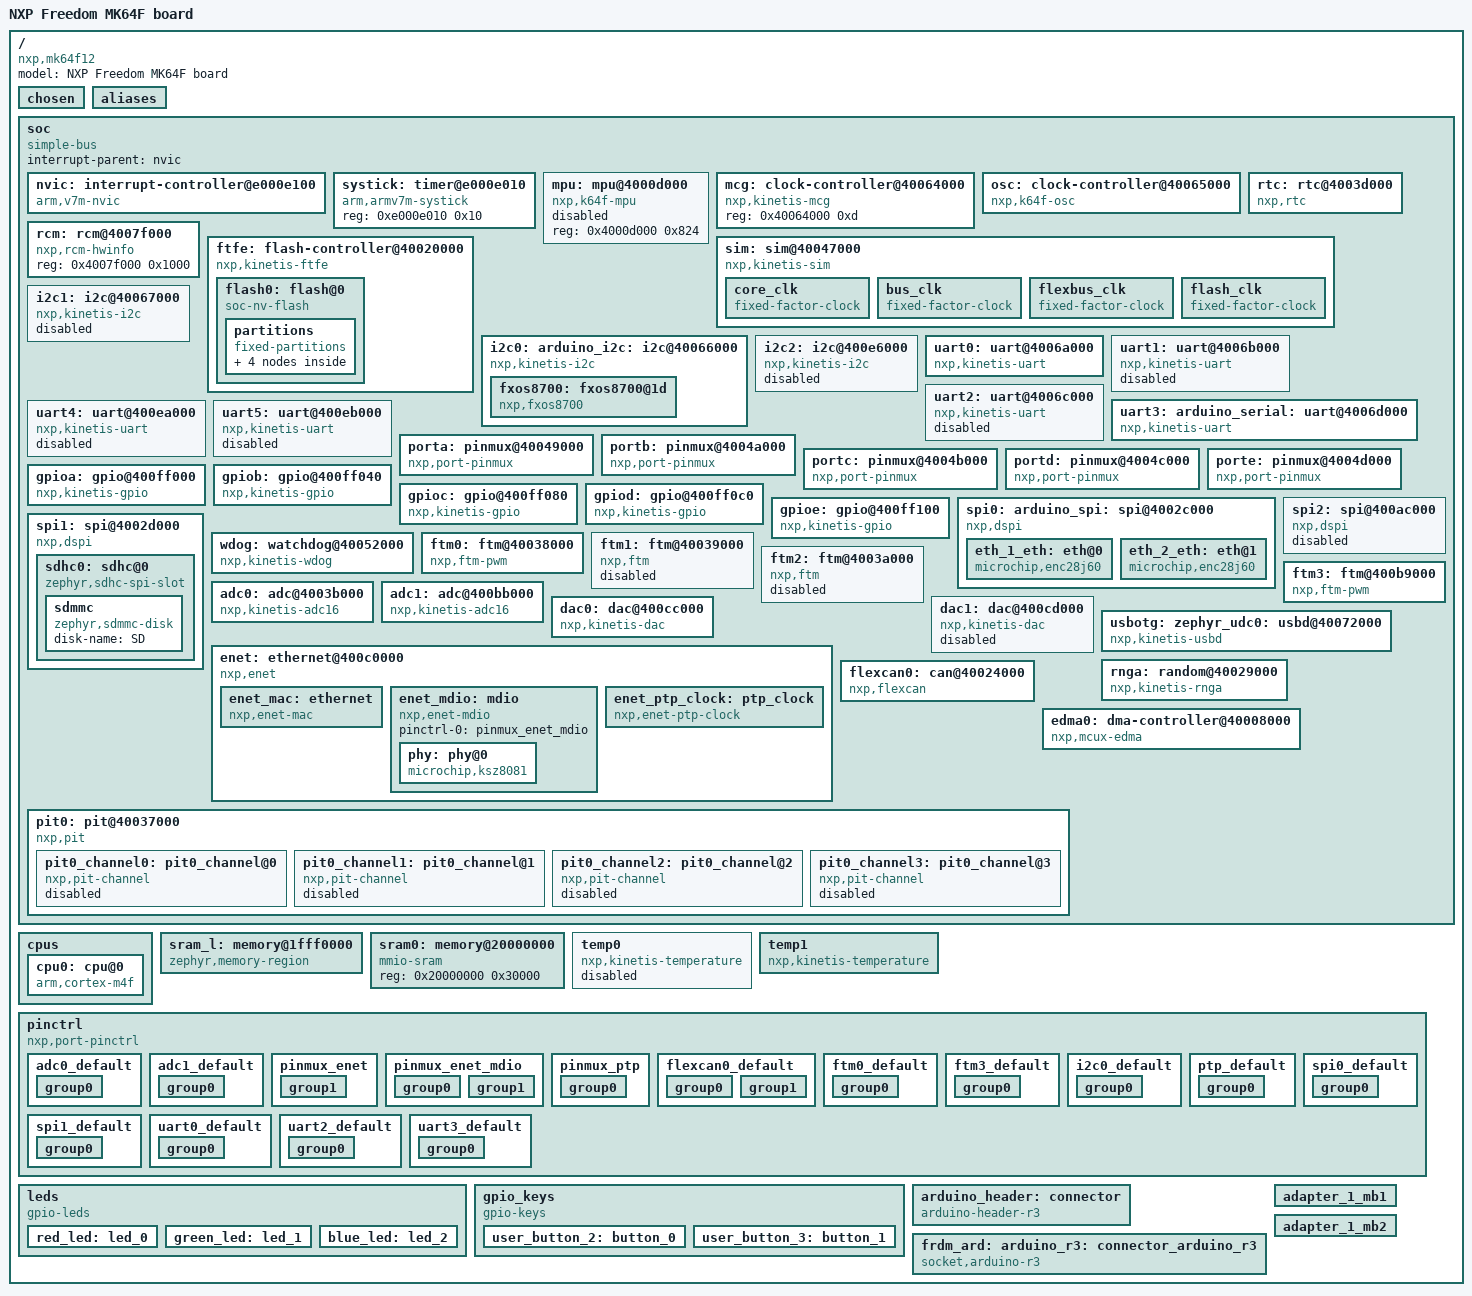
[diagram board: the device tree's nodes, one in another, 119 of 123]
/dts-v1/;

/* node '/' defined in zephyr/dts/common/skeleton.dtsi:9 */
/ {
	#address-cells = < 0x1 >;          /* in zephyr/dts/common/skeleton.dtsi:10 */
	#size-cells = < 0x1 >;             /* in zephyr/dts/common/skeleton.dtsi:11 */
	model = "NXP Freedom MK64F board"; /* in zephyr/boards/nxp/frdm_k64f/frdm_k64f.dts:15 */
	compatible = "nxp,mk64f12",
	             "nxp,k64f",
	             "nxp,k6x";            /* in zephyr/boards/nxp/frdm_k64f/frdm_k64f.dts:16 */

	/* node '/chosen' defined in zephyr/dts/common/skeleton.dtsi:13 */
	chosen {
		zephyr,entropy = &rnga;                   /* in zephyr/dts/arm/nxp/kinetis/nxp_k6x.dtsi:22 */
		zephyr,flash-controller = &ftfe;          /* in zephyr/dts/arm/nxp/kinetis/nxp_k6x.dtsi:23 */
		zephyr,sram = &sram0;                     /* in zephyr/boards/nxp/frdm_k64f/frdm_k64f.dts:30 */
		zephyr,flash = &flash0;                   /* in zephyr/boards/nxp/frdm_k64f/frdm_k64f.dts:31 */
		zephyr,code-partition = &slot0_partition; /* in zephyr/boards/nxp/frdm_k64f/frdm_k64f.dts:32 */
		zephyr,console = &uart0;                  /* in zephyr/boards/nxp/frdm_k64f/frdm_k64f.dts:33 */
		zephyr,shell-uart = &uart0;               /* in zephyr/boards/nxp/frdm_k64f/frdm_k64f.dts:34 */
		zephyr,uart-pipe = &uart0;                /* in zephyr/boards/nxp/frdm_k64f/frdm_k64f.dts:35 */
		zephyr,canbus = &flexcan0;                /* in zephyr/boards/nxp/frdm_k64f/frdm_k64f.dts:36 */
		zephyr,uart-mcumgr = &uart0;              /* in zephyr/boards/nxp/frdm_k64f/frdm_k64f.dts:37 */
	};

	/* node '/aliases' defined in zephyr/dts/common/skeleton.dtsi:15 */
	aliases {
		watchdog0 = &wdog;                /* in zephyr/dts/arm/nxp/kinetis/nxp_k6x.dtsi:18 */
		led0 = &green_led;                /* in zephyr/boards/nxp/frdm_k64f/frdm_k64f.dts:19 */
		led1 = &blue_led;                 /* in zephyr/boards/nxp/frdm_k64f/frdm_k64f.dts:20 */
		led2 = &red_led;                  /* in zephyr/boards/nxp/frdm_k64f/frdm_k64f.dts:21 */
		sw0 = &user_button_3;             /* in zephyr/boards/nxp/frdm_k64f/frdm_k64f.dts:22 */
		sw1 = &user_button_2;             /* in zephyr/boards/nxp/frdm_k64f/frdm_k64f.dts:23 */
		magn0 = &fxos8700;                /* in zephyr/boards/nxp/frdm_k64f/frdm_k64f.dts:24 */
		accel0 = &fxos8700;               /* in zephyr/boards/nxp/frdm_k64f/frdm_k64f.dts:25 */
		mcuboot-button0 = &user_button_2; /* in zephyr/boards/nxp/frdm_k64f/frdm_k64f.dts:26 */
	};

	/* node '/soc' defined in zephyr/dts/arm/armv7-m.dtsi:6 */
	soc {
		#address-cells = < 0x1 >;     /* in zephyr/dts/arm/armv7-m.dtsi:7 */
		#size-cells = < 0x1 >;        /* in zephyr/dts/arm/armv7-m.dtsi:8 */
		compatible = "simple-bus";    /* in zephyr/dts/arm/armv7-m.dtsi:9 */
		interrupt-parent = < &nvic >; /* in zephyr/dts/arm/armv7-m.dtsi:10 */
		ranges;                       /* in zephyr/dts/arm/armv7-m.dtsi:11 */

		/* node '/soc/interrupt-controller@e000e100' defined in zephyr/dts/arm/armv7-m.dtsi:13 */
		nvic: interrupt-controller@e000e100 {
			#address-cells = < 0x1 >;            /* in zephyr/dts/arm/armv7-m.dtsi:14 */
			compatible = "arm,v7m-nvic";         /* in zephyr/dts/arm/armv7-m.dtsi:15 */
			reg = < 0xe000e100 0xc00 >;          /* in zephyr/dts/arm/armv7-m.dtsi:16 */
			interrupt-controller;                /* in zephyr/dts/arm/armv7-m.dtsi:17 */
			#interrupt-cells = < 0x2 >;          /* in zephyr/dts/arm/armv7-m.dtsi:18 */
			arm,num-irq-priority-bits = < 0x4 >; /* in zephyr/dts/arm/nxp/kinetis/nxp_k6x.dtsi:599 */
			phandle = < 0x1 >;                   /* in zephyr/dts/arm/armv7-m.dtsi:10 */
		};

		/* node '/soc/timer@e000e010' defined in zephyr/dts/arm/armv7-m.dtsi:21 */
		systick: timer@e000e010 {
			compatible = "arm,armv7m-systick"; /* in zephyr/dts/arm/armv7-m.dtsi:22 */
			reg = < 0xe000e010 0x10 >;         /* in zephyr/dts/arm/armv7-m.dtsi:23 */
		};

		/* node '/soc/mpu@4000d000' defined in zephyr/dts/arm/nxp/kinetis/nxp_k6x.dtsi:86 */
		mpu: mpu@4000d000 {
			compatible = "nxp,k64f-mpu"; /* in zephyr/dts/arm/nxp/kinetis/nxp_k6x.dtsi:87 */
			reg = < 0x4000d000 0x824 >;  /* in zephyr/dts/arm/nxp/kinetis/nxp_k6x.dtsi:88 */
			status = "disabled";         /* in zephyr/dts/arm/nxp/kinetis/nxp_k6x.dtsi:90 */
		};

		/* node '/soc/clock-controller@40064000' defined in zephyr/dts/arm/nxp/kinetis/nxp_k6x.dtsi:93 */
		mcg: clock-controller@40064000 {
			compatible = "nxp,kinetis-mcg"; /* in zephyr/dts/arm/nxp/kinetis/nxp_k6x.dtsi:94 */
			reg = < 0x40064000 0xd >;       /* in zephyr/dts/arm/nxp/kinetis/nxp_k6x.dtsi:95 */
			#clock-cells = < 0x1 >;         /* in zephyr/dts/arm/nxp/kinetis/nxp_k6x.dtsi:96 */
			phandle = < 0x2 >;              /* in zephyr/dts/arm/nxp/kinetis/nxp_k6x.dtsi:127 */
		};

		/* node '/soc/clock-controller@40065000' defined in zephyr/dts/arm/nxp/kinetis/nxp_k6x.dtsi:99 */
		osc: clock-controller@40065000 {
			compatible = "nxp,k64f-osc"; /* in zephyr/dts/arm/nxp/kinetis/nxp_k6x.dtsi:100 */
			reg = < 0x40065000 0x4 >;    /* in zephyr/dts/arm/nxp/kinetis/nxp_k6x.dtsi:101 */
			enable-external-reference;   /* in zephyr/dts/arm/nxp/kinetis/nxp_k6x.dtsi:103 */
		};

		/* node '/soc/rtc@4003d000' defined in zephyr/dts/arm/nxp/kinetis/nxp_k6x.dtsi:106 */
		rtc: rtc@4003d000 {
			compatible = "nxp,rtc";       /* in zephyr/dts/arm/nxp/kinetis/nxp_k6x.dtsi:107 */
			reg = < 0x4003d000 0x1000 >;  /* in zephyr/dts/arm/nxp/kinetis/nxp_k6x.dtsi:108 */
			interrupts = < 0x2e 0x0 >,
			             < 0x2f 0x0 >;    /* in zephyr/dts/arm/nxp/kinetis/nxp_k6x.dtsi:109 */
			interrupt-names = "alarm",
			                  "seconds";  /* in zephyr/dts/arm/nxp/kinetis/nxp_k6x.dtsi:110 */
			clock-frequency = < 0x8000 >; /* in zephyr/dts/arm/nxp/kinetis/nxp_k6x.dtsi:111 */
			prescaler = < 0x8000 >;       /* in zephyr/dts/arm/nxp/kinetis/nxp_k6x.dtsi:112 */
		};

		/* node '/soc/rcm@4007f000' defined in zephyr/dts/arm/nxp/kinetis/nxp_k6x.dtsi:115 */
		rcm: rcm@4007f000 {
			compatible = "nxp,rcm-hwinfo"; /* in zephyr/dts/arm/nxp/kinetis/nxp_k6x.dtsi:116 */
			reg = < 0x4007f000 0x1000 >;   /* in zephyr/dts/arm/nxp/kinetis/nxp_k6x.dtsi:117 */
		};

		/* node '/soc/sim@40047000' defined in zephyr/dts/arm/nxp/kinetis/nxp_k6x.dtsi:120 */
		sim: sim@40047000 {
			compatible = "nxp,kinetis-sim",
			             "nxp,sim-uuid";    /* in zephyr/dts/arm/nxp/kinetis/nxp_k6x.dtsi:121 */
			reg = < 0x40047000 0x1060 >;    /* in zephyr/dts/arm/nxp/kinetis/nxp_k6x.dtsi:122 */
			#clock-cells = < 0x3 >;         /* in zephyr/dts/arm/nxp/kinetis/nxp_k6x.dtsi:123 */
			pllfll-select = < 0x1 >;        /* in zephyr/boards/nxp/frdm_k64f/frdm_k64f.dts:109 */
			er32k-select = < 0x2 >;         /* in zephyr/boards/nxp/frdm_k64f/frdm_k64f.dts:110 */
			phandle = < 0x3 >;              /* in zephyr/dts/arm/nxp/kinetis/nxp_k6x.dtsi:179 */

			/* node '/soc/sim@40047000/core_clk' defined in zephyr/dts/arm/nxp/kinetis/nxp_k6x.dtsi:125 */
			core_clk {
				compatible = "fixed-factor-clock"; /* in zephyr/dts/arm/nxp/kinetis/nxp_k6x.dtsi:126 */
				clocks = < &mcg 0x1 >;             /* in zephyr/dts/arm/nxp/kinetis/nxp_k6x.dtsi:127 */
				clock-div = < 0x1 >;               /* in zephyr/dts/arm/nxp/kinetis/nxp_k6x.dtsi:128 */
				#clock-cells = < 0x0 >;            /* in zephyr/dts/arm/nxp/kinetis/nxp_k6x.dtsi:129 */
			};

			/* node '/soc/sim@40047000/bus_clk' defined in zephyr/dts/arm/nxp/kinetis/nxp_k6x.dtsi:132 */
			bus_clk {
				compatible = "fixed-factor-clock"; /* in zephyr/dts/arm/nxp/kinetis/nxp_k6x.dtsi:133 */
				clocks = < &mcg 0x1 >;             /* in zephyr/dts/arm/nxp/kinetis/nxp_k6x.dtsi:134 */
				clock-div = < 0x2 >;               /* in zephyr/dts/arm/nxp/kinetis/nxp_k6x.dtsi:135 */
				#clock-cells = < 0x0 >;            /* in zephyr/dts/arm/nxp/kinetis/nxp_k6x.dtsi:136 */
			};

			/* node '/soc/sim@40047000/flexbus_clk' defined in zephyr/dts/arm/nxp/kinetis/nxp_k6x.dtsi:139 */
			flexbus_clk {
				compatible = "fixed-factor-clock"; /* in zephyr/dts/arm/nxp/kinetis/nxp_k6x.dtsi:140 */
				clocks = < &mcg 0x1 >;             /* in zephyr/dts/arm/nxp/kinetis/nxp_k6x.dtsi:141 */
				clock-div = < 0x3 >;               /* in zephyr/dts/arm/nxp/kinetis/nxp_k6x.dtsi:142 */
				#clock-cells = < 0x0 >;            /* in zephyr/dts/arm/nxp/kinetis/nxp_k6x.dtsi:143 */
			};

			/* node '/soc/sim@40047000/flash_clk' defined in zephyr/dts/arm/nxp/kinetis/nxp_k6x.dtsi:146 */
			flash_clk {
				compatible = "fixed-factor-clock"; /* in zephyr/dts/arm/nxp/kinetis/nxp_k6x.dtsi:147 */
				clocks = < &mcg 0x1 >;             /* in zephyr/dts/arm/nxp/kinetis/nxp_k6x.dtsi:148 */
				clock-div = < 0x5 >;               /* in zephyr/dts/arm/nxp/kinetis/nxp_k6x.dtsi:149 */
				#clock-cells = < 0x0 >;            /* in zephyr/dts/arm/nxp/kinetis/nxp_k6x.dtsi:150 */
			};
		};

		/* node '/soc/flash-controller@40020000' defined in zephyr/dts/arm/nxp/kinetis/nxp_k6x.dtsi:154 */
		ftfe: flash-controller@40020000 {
			compatible = "nxp,kinetis-ftfe";      /* in zephyr/dts/arm/nxp/kinetis/nxp_k6x.dtsi:155 */
			reg = < 0x40020000 0x18 >;            /* in zephyr/dts/arm/nxp/kinetis/nxp_k6x.dtsi:156 */
			interrupts = < 0x12 0x0 >,
			             < 0x13 0x0 >;            /* in zephyr/dts/arm/nxp/kinetis/nxp_k6x.dtsi:157 */
			interrupt-names = "command-complete",
			                  "read-collision";   /* in zephyr/dts/arm/nxp/kinetis/nxp_k6x.dtsi:158 */
			status = "okay";                      /* in zephyr/dts/arm/nxp/kinetis/nxp_k6x.dtsi:159 */
			#address-cells = < 0x1 >;             /* in zephyr/dts/arm/nxp/kinetis/nxp_k6x.dtsi:161 */
			#size-cells = < 0x1 >;                /* in zephyr/dts/arm/nxp/kinetis/nxp_k6x.dtsi:162 */

			/* node '/soc/flash-controller@40020000/flash@0' defined in zephyr/dts/arm/nxp/kinetis/nxp_k6x.dtsi:164 */
			flash0: flash@0 {
				compatible = "soc-nv-flash";   /* in zephyr/dts/arm/nxp/kinetis/nxp_k6x.dtsi:165 */
				reg = < 0x0 0x100000 >;        /* in zephyr/dts/arm/nxp/kinetis/nxp_k6x.dtsi:166 */
				erase-block-size = < 0x1000 >; /* in zephyr/dts/arm/nxp/kinetis/nxp_k6x.dtsi:167 */
				write-block-size = < 0x8 >;    /* in zephyr/dts/arm/nxp/kinetis/nxp_k6x.dtsi:168 */

				/* node '/soc/flash-controller@40020000/flash@0/partitions' defined in zephyr/boards/nxp/frdm_k64f/frdm_k64f.dts:242 */
				partitions {
					compatible = "fixed-partitions"; /* in zephyr/boards/nxp/frdm_k64f/frdm_k64f.dts:243 */
					#address-cells = < 0x1 >;        /* in zephyr/boards/nxp/frdm_k64f/frdm_k64f.dts:244 */
					#size-cells = < 0x1 >;           /* in zephyr/boards/nxp/frdm_k64f/frdm_k64f.dts:245 */

					/* node '/soc/flash-controller@40020000/flash@0/partitions/partition@0' defined in zephyr/boards/nxp/frdm_k64f/frdm_k64f.dts:251 */
					boot_partition: partition@0 {
						label = "mcuboot";     /* in zephyr/boards/nxp/frdm_k64f/frdm_k64f.dts:252 */
						reg = < 0x0 0x10000 >; /* in zephyr/boards/nxp/frdm_k64f/frdm_k64f.dts:253 */
						read-only;             /* in zephyr/boards/nxp/frdm_k64f/frdm_k64f.dts:254 */
					};

					/* node '/soc/flash-controller@40020000/flash@0/partitions/partition@10000' defined in zephyr/boards/nxp/frdm_k64f/frdm_k64f.dts:257 */
					slot0_partition: partition@10000 {
						label = "image-0";         /* in zephyr/boards/nxp/frdm_k64f/frdm_k64f.dts:258 */
						reg = < 0x10000 0x69000 >; /* in zephyr/boards/nxp/frdm_k64f/frdm_k64f.dts:259 */
					};

					/* node '/soc/flash-controller@40020000/flash@0/partitions/partition@79000' defined in zephyr/boards/nxp/frdm_k64f/frdm_k64f.dts:262 */
					slot1_partition: partition@79000 {
						label = "image-1";         /* in zephyr/boards/nxp/frdm_k64f/frdm_k64f.dts:263 */
						reg = < 0x79000 0x69000 >; /* in zephyr/boards/nxp/frdm_k64f/frdm_k64f.dts:264 */
					};

					/* node '/soc/flash-controller@40020000/flash@0/partitions/partition@e2000' defined in zephyr/boards/nxp/frdm_k64f/frdm_k64f.dts:267 */
					storage_partition: partition@e2000 {
						label = "storage";         /* in zephyr/boards/nxp/frdm_k64f/frdm_k64f.dts:268 */
						reg = < 0xe2000 0x1e000 >; /* in zephyr/boards/nxp/frdm_k64f/frdm_k64f.dts:269 */
					};
				};
			};
		};

		/* node '/soc/i2c@40066000' defined in zephyr/dts/arm/nxp/kinetis/nxp_k6x.dtsi:172 */
		i2c0: arduino_i2c: i2c@40066000 {
			compatible = "nxp,kinetis-i2c";          /* in zephyr/dts/arm/nxp/kinetis/nxp_k6x.dtsi:173 */
			clock-frequency = < 0x186a0 >;           /* in zephyr/dts/arm/nxp/kinetis/nxp_k6x.dtsi:174 */
			#address-cells = < 0x1 >;                /* in zephyr/dts/arm/nxp/kinetis/nxp_k6x.dtsi:175 */
			#size-cells = < 0x0 >;                   /* in zephyr/dts/arm/nxp/kinetis/nxp_k6x.dtsi:176 */
			reg = < 0x40066000 0x1000 >;             /* in zephyr/dts/arm/nxp/kinetis/nxp_k6x.dtsi:177 */
			interrupts = < 0x18 0x0 >;               /* in zephyr/dts/arm/nxp/kinetis/nxp_k6x.dtsi:178 */
			clocks = < &sim 0x81a18400 0x1034 0x6 >; /* in zephyr/dts/arm/nxp/kinetis/nxp_k6x.dtsi:179 */
			status = "okay";                         /* in zephyr/boards/nxp/frdm_k64f/frdm_k64f.dts:146 */
			pinctrl-0 = < &i2c0_default >;           /* in zephyr/boards/nxp/frdm_k64f/frdm_k64f.dts:147 */
			pinctrl-names = "default";               /* in zephyr/boards/nxp/frdm_k64f/frdm_k64f.dts:148 */
			phandle = < 0x24 >;                      /* in btr-shields/boards/extend/nxp/frdm_k64f/arduino_r3_socket.dtsi:59 */

			/* node '/soc/i2c@40066000/fxos8700@1d' defined in zephyr/boards/nxp/frdm_k64f/frdm_k64f.dts:150 */
			fxos8700: fxos8700@1d {
				compatible = "nxp,fxos8700";     /* in zephyr/boards/nxp/frdm_k64f/frdm_k64f.dts:151 */
				reg = < 0x1d >;                  /* in zephyr/boards/nxp/frdm_k64f/frdm_k64f.dts:152 */
				int1-gpios = < &gpioc 0x6 0x1 >; /* in zephyr/boards/nxp/frdm_k64f/frdm_k64f.dts:153 */
				int2-gpios = < &gpioc 0xd 0x1 >; /* in zephyr/boards/nxp/frdm_k64f/frdm_k64f.dts:154 */
			};
		};

		/* node '/soc/i2c@40067000' defined in zephyr/dts/arm/nxp/kinetis/nxp_k6x.dtsi:183 */
		i2c1: i2c@40067000 {
			compatible = "nxp,kinetis-i2c";          /* in zephyr/dts/arm/nxp/kinetis/nxp_k6x.dtsi:184 */
			clock-frequency = < 0x186a0 >;           /* in zephyr/dts/arm/nxp/kinetis/nxp_k6x.dtsi:185 */
			#address-cells = < 0x1 >;                /* in zephyr/dts/arm/nxp/kinetis/nxp_k6x.dtsi:186 */
			#size-cells = < 0x0 >;                   /* in zephyr/dts/arm/nxp/kinetis/nxp_k6x.dtsi:187 */
			reg = < 0x40067000 0x1000 >;             /* in zephyr/dts/arm/nxp/kinetis/nxp_k6x.dtsi:188 */
			interrupts = < 0x19 0x0 >;               /* in zephyr/dts/arm/nxp/kinetis/nxp_k6x.dtsi:189 */
			clocks = < &sim 0x81a1c400 0x1034 0x7 >; /* in zephyr/dts/arm/nxp/kinetis/nxp_k6x.dtsi:190 */
			status = "disabled";                     /* in zephyr/dts/arm/nxp/kinetis/nxp_k6x.dtsi:191 */
		};

		/* node '/soc/i2c@400e6000' defined in zephyr/dts/arm/nxp/kinetis/nxp_k6x.dtsi:194 */
		i2c2: i2c@400e6000 {
			compatible = "nxp,kinetis-i2c";          /* in zephyr/dts/arm/nxp/kinetis/nxp_k6x.dtsi:195 */
			clock-frequency = < 0x186a0 >;           /* in zephyr/dts/arm/nxp/kinetis/nxp_k6x.dtsi:196 */
			#address-cells = < 0x1 >;                /* in zephyr/dts/arm/nxp/kinetis/nxp_k6x.dtsi:197 */
			#size-cells = < 0x0 >;                   /* in zephyr/dts/arm/nxp/kinetis/nxp_k6x.dtsi:198 */
			reg = < 0x400e6000 0x1000 >;             /* in zephyr/dts/arm/nxp/kinetis/nxp_k6x.dtsi:199 */
			interrupts = < 0x4a 0x0 >;               /* in zephyr/dts/arm/nxp/kinetis/nxp_k6x.dtsi:200 */
			clocks = < &sim 0x81418400 0x1028 0x6 >; /* in zephyr/dts/arm/nxp/kinetis/nxp_k6x.dtsi:201 */
			status = "disabled";                     /* in zephyr/dts/arm/nxp/kinetis/nxp_k6x.dtsi:202 */
		};

		/* node '/soc/uart@4006a000' defined in zephyr/dts/arm/nxp/kinetis/nxp_k6x.dtsi:205 */
		uart0: uart@4006a000 {
			compatible = "nxp,kinetis-uart";         /* in zephyr/dts/arm/nxp/kinetis/nxp_k6x.dtsi:206 */
			reg = < 0x4006a000 0x1000 >;             /* in zephyr/dts/arm/nxp/kinetis/nxp_k6x.dtsi:207 */
			interrupts = < 0x1f 0x0 >,
			             < 0x20 0x0 >;               /* in zephyr/dts/arm/nxp/kinetis/nxp_k6x.dtsi:208 */
			interrupt-names = "status",
			                  "error";               /* in zephyr/dts/arm/nxp/kinetis/nxp_k6x.dtsi:209 */
			clocks = < &sim 0x81a28000 0x1034 0xa >; /* in zephyr/dts/arm/nxp/kinetis/nxp_k6x.dtsi:210 */
			status = "okay";                         /* in zephyr/boards/nxp/frdm_k64f/frdm_k64f.dts:204 */
			current-speed = < 0x1c200 >;             /* in zephyr/boards/nxp/frdm_k64f/frdm_k64f.dts:205 */
			pinctrl-0 = < &uart0_default >;          /* in zephyr/boards/nxp/frdm_k64f/frdm_k64f.dts:206 */
			pinctrl-names = "default";               /* in zephyr/boards/nxp/frdm_k64f/frdm_k64f.dts:207 */
		};

		/* node '/soc/uart@4006b000' defined in zephyr/dts/arm/nxp/kinetis/nxp_k6x.dtsi:215 */
		uart1: uart@4006b000 {
			compatible = "nxp,kinetis-uart";         /* in zephyr/dts/arm/nxp/kinetis/nxp_k6x.dtsi:216 */
			reg = < 0x4006b000 0x1000 >;             /* in zephyr/dts/arm/nxp/kinetis/nxp_k6x.dtsi:217 */
			interrupts = < 0x21 0x0 >,
			             < 0x22 0x0 >;               /* in zephyr/dts/arm/nxp/kinetis/nxp_k6x.dtsi:218 */
			interrupt-names = "status",
			                  "error";               /* in zephyr/dts/arm/nxp/kinetis/nxp_k6x.dtsi:219 */
			clocks = < &sim 0x81a2c000 0x1034 0xb >; /* in zephyr/dts/arm/nxp/kinetis/nxp_k6x.dtsi:220 */
			status = "disabled";                     /* in zephyr/dts/arm/nxp/kinetis/nxp_k6x.dtsi:222 */
		};

		/* node '/soc/uart@4006c000' defined in zephyr/dts/arm/nxp/kinetis/nxp_k6x.dtsi:225 */
		uart2: uart@4006c000 {
			compatible = "nxp,kinetis-uart";         /* in zephyr/dts/arm/nxp/kinetis/nxp_k6x.dtsi:226 */
			reg = < 0x4006c000 0x1000 >;             /* in zephyr/dts/arm/nxp/kinetis/nxp_k6x.dtsi:227 */
			interrupts = < 0x23 0x0 >,
			             < 0x24 0x0 >;               /* in zephyr/dts/arm/nxp/kinetis/nxp_k6x.dtsi:228 */
			interrupt-names = "status",
			                  "error";               /* in zephyr/dts/arm/nxp/kinetis/nxp_k6x.dtsi:229 */
			clocks = < &sim 0x81a30400 0x1034 0xc >; /* in zephyr/dts/arm/nxp/kinetis/nxp_k6x.dtsi:230 */
			status = "disabled";                     /* in zephyr/dts/arm/nxp/kinetis/nxp_k6x.dtsi:232 */
			pinctrl-0 = < &uart2_default >;          /* in zephyr/boards/nxp/frdm_k64f/frdm_k64f.dts:211 */
			pinctrl-names = "default";               /* in zephyr/boards/nxp/frdm_k64f/frdm_k64f.dts:212 */
		};

		/* node '/soc/uart@4006d000' defined in zephyr/dts/arm/nxp/kinetis/nxp_k6x.dtsi:235 */
		uart3: arduino_serial: uart@4006d000 {
			compatible = "nxp,kinetis-uart";         /* in zephyr/dts/arm/nxp/kinetis/nxp_k6x.dtsi:236 */
			reg = < 0x4006d000 0x1000 >;             /* in zephyr/dts/arm/nxp/kinetis/nxp_k6x.dtsi:237 */
			interrupts = < 0x25 0x0 >,
			             < 0x26 0x0 >;               /* in zephyr/dts/arm/nxp/kinetis/nxp_k6x.dtsi:238 */
			interrupt-names = "status",
			                  "error";               /* in zephyr/dts/arm/nxp/kinetis/nxp_k6x.dtsi:239 */
			clocks = < &sim 0x81a34400 0x1034 0xd >; /* in zephyr/dts/arm/nxp/kinetis/nxp_k6x.dtsi:240 */
			status = "okay";                         /* in zephyr/boards/nxp/frdm_k64f/frdm_k64f.dts:114 */
			current-speed = < 0x1c200 >;             /* in zephyr/boards/nxp/frdm_k64f/frdm_k64f.dts:115 */
			pinctrl-0 = < &uart3_default >;          /* in zephyr/boards/nxp/frdm_k64f/frdm_k64f.dts:116 */
			pinctrl-names = "default";               /* in zephyr/boards/nxp/frdm_k64f/frdm_k64f.dts:117 */
			phandle = < 0x26 >;                      /* in btr-shields/boards/extend/nxp/frdm_k64f/arduino_r3_socket.dtsi:61 */
		};

		/* node '/soc/uart@400ea000' defined in zephyr/dts/arm/nxp/kinetis/nxp_k6x.dtsi:245 */
		uart4: uart@400ea000 {
			compatible = "nxp,kinetis-uart";         /* in zephyr/dts/arm/nxp/kinetis/nxp_k6x.dtsi:246 */
			reg = < 0x400ea000 0x1000 >;             /* in zephyr/dts/arm/nxp/kinetis/nxp_k6x.dtsi:247 */
			interrupts = < 0x42 0x0 >,
			             < 0x43 0x0 >;               /* in zephyr/dts/arm/nxp/kinetis/nxp_k6x.dtsi:248 */
			interrupt-names = "status",
			                  "error";               /* in zephyr/dts/arm/nxp/kinetis/nxp_k6x.dtsi:249 */
			clocks = < &sim 0x81428400 0x1028 0xa >; /* in zephyr/dts/arm/nxp/kinetis/nxp_k6x.dtsi:250 */
			status = "disabled";                     /* in zephyr/dts/arm/nxp/kinetis/nxp_k6x.dtsi:252 */
		};

		/* node '/soc/uart@400eb000' defined in zephyr/dts/arm/nxp/kinetis/nxp_k6x.dtsi:255 */
		uart5: uart@400eb000 {
			compatible = "nxp,kinetis-uart";         /* in zephyr/dts/arm/nxp/kinetis/nxp_k6x.dtsi:256 */
			reg = < 0x400eb000 0x1000 >;             /* in zephyr/dts/arm/nxp/kinetis/nxp_k6x.dtsi:257 */
			interrupts = < 0x44 0x0 >,
			             < 0x45 0x0 >;               /* in zephyr/dts/arm/nxp/kinetis/nxp_k6x.dtsi:258 */
			interrupt-names = "status",
			                  "error";               /* in zephyr/dts/arm/nxp/kinetis/nxp_k6x.dtsi:259 */
			clocks = < &sim 0x8142c400 0x1028 0xb >; /* in zephyr/dts/arm/nxp/kinetis/nxp_k6x.dtsi:260 */
			status = "disabled";                     /* in zephyr/dts/arm/nxp/kinetis/nxp_k6x.dtsi:262 */
		};

		/* node '/soc/pinmux@40049000' defined in zephyr/dts/arm/nxp/kinetis/nxp_k6x.dtsi:265 */
		porta: pinmux@40049000 {
			compatible = "nxp,port-pinmux";          /* in zephyr/dts/arm/nxp/kinetis/nxp_k6x.dtsi:266 */
			reg = < 0x40049000 0xd0 >;               /* in zephyr/dts/arm/nxp/kinetis/nxp_k6x.dtsi:267 */
			clocks = < &sim 0x81c24400 0x1038 0x9 >; /* in zephyr/dts/arm/nxp/kinetis/nxp_k6x.dtsi:268 */
			phandle = < 0x9 >;                       /* in zephyr/dts/arm/nxp/kinetis/nxp_k6x.dtsi:302 */
		};

		/* node '/soc/pinmux@4004a000' defined in zephyr/dts/arm/nxp/kinetis/nxp_k6x.dtsi:271 */
		portb: pinmux@4004a000 {
			compatible = "nxp,port-pinmux";          /* in zephyr/dts/arm/nxp/kinetis/nxp_k6x.dtsi:272 */
			reg = < 0x4004a000 0xd0 >;               /* in zephyr/dts/arm/nxp/kinetis/nxp_k6x.dtsi:273 */
			clocks = < &sim 0x81c28400 0x1038 0xa >; /* in zephyr/dts/arm/nxp/kinetis/nxp_k6x.dtsi:274 */
			phandle = < 0xa >;                       /* in zephyr/dts/arm/nxp/kinetis/nxp_k6x.dtsi:312 */
		};

		/* node '/soc/pinmux@4004b000' defined in zephyr/dts/arm/nxp/kinetis/nxp_k6x.dtsi:277 */
		portc: pinmux@4004b000 {
			compatible = "nxp,port-pinmux";          /* in zephyr/dts/arm/nxp/kinetis/nxp_k6x.dtsi:278 */
			reg = < 0x4004b000 0xd0 >;               /* in zephyr/dts/arm/nxp/kinetis/nxp_k6x.dtsi:279 */
			clocks = < &sim 0x81c2c400 0x1038 0xb >; /* in zephyr/dts/arm/nxp/kinetis/nxp_k6x.dtsi:280 */
			phandle = < 0xb >;                       /* in zephyr/dts/arm/nxp/kinetis/nxp_k6x.dtsi:322 */
		};

		/* node '/soc/pinmux@4004c000' defined in zephyr/dts/arm/nxp/kinetis/nxp_k6x.dtsi:283 */
		portd: pinmux@4004c000 {
			compatible = "nxp,port-pinmux";          /* in zephyr/dts/arm/nxp/kinetis/nxp_k6x.dtsi:284 */
			reg = < 0x4004c000 0xd0 >;               /* in zephyr/dts/arm/nxp/kinetis/nxp_k6x.dtsi:285 */
			clocks = < &sim 0x81c30400 0x1038 0xc >; /* in zephyr/dts/arm/nxp/kinetis/nxp_k6x.dtsi:286 */
			phandle = < 0xc >;                       /* in zephyr/dts/arm/nxp/kinetis/nxp_k6x.dtsi:332 */
		};

		/* node '/soc/pinmux@4004d000' defined in zephyr/dts/arm/nxp/kinetis/nxp_k6x.dtsi:289 */
		porte: pinmux@4004d000 {
			compatible = "nxp,port-pinmux";          /* in zephyr/dts/arm/nxp/kinetis/nxp_k6x.dtsi:290 */
			reg = < 0x4004d000 0xd0 >;               /* in zephyr/dts/arm/nxp/kinetis/nxp_k6x.dtsi:291 */
			clocks = < &sim 0x81c34400 0x1038 0xd >; /* in zephyr/dts/arm/nxp/kinetis/nxp_k6x.dtsi:292 */
			phandle = < 0xd >;                       /* in zephyr/dts/arm/nxp/kinetis/nxp_k6x.dtsi:342 */
		};

		/* node '/soc/gpio@400ff000' defined in zephyr/dts/arm/nxp/kinetis/nxp_k6x.dtsi:295 */
		gpioa: gpio@400ff000 {
			compatible = "nxp,kinetis-gpio"; /* in zephyr/dts/arm/nxp/kinetis/nxp_k6x.dtsi:296 */
			reg = < 0x400ff000 0x40 >;       /* in zephyr/dts/arm/nxp/kinetis/nxp_k6x.dtsi:298 */
			interrupts = < 0x3b 0x2 >;       /* in zephyr/dts/arm/nxp/kinetis/nxp_k6x.dtsi:299 */
			gpio-controller;                 /* in zephyr/dts/arm/nxp/kinetis/nxp_k6x.dtsi:300 */
			#gpio-cells = < 0x2 >;           /* in zephyr/dts/arm/nxp/kinetis/nxp_k6x.dtsi:301 */
			nxp,kinetis-port = < &porta >;   /* in zephyr/dts/arm/nxp/kinetis/nxp_k6x.dtsi:302 */
			status = "okay";                 /* in zephyr/boards/nxp/frdm_k64f/frdm_k64f.dts:222 */
			phandle = < 0x22 >;              /* in zephyr/boards/nxp/frdm_k64f/frdm_k64f.dts:70 */
		};

		/* node '/soc/gpio@400ff040' defined in zephyr/dts/arm/nxp/kinetis/nxp_k6x.dtsi:305 */
		gpiob: gpio@400ff040 {
			compatible = "nxp,kinetis-gpio"; /* in zephyr/dts/arm/nxp/kinetis/nxp_k6x.dtsi:306 */
			reg = < 0x400ff040 0x40 >;       /* in zephyr/dts/arm/nxp/kinetis/nxp_k6x.dtsi:308 */
			interrupts = < 0x3c 0x2 >;       /* in zephyr/dts/arm/nxp/kinetis/nxp_k6x.dtsi:309 */
			gpio-controller;                 /* in zephyr/dts/arm/nxp/kinetis/nxp_k6x.dtsi:310 */
			#gpio-cells = < 0x2 >;           /* in zephyr/dts/arm/nxp/kinetis/nxp_k6x.dtsi:311 */
			nxp,kinetis-port = < &portb >;   /* in zephyr/dts/arm/nxp/kinetis/nxp_k6x.dtsi:312 */
			status = "okay";                 /* in zephyr/boards/nxp/frdm_k64f/frdm_k64f.dts:226 */
			phandle = < 0x21 >;              /* in zephyr/boards/nxp/frdm_k64f/frdm_k64f.dts:44 */
		};

		/* node '/soc/gpio@400ff080' defined in zephyr/dts/arm/nxp/kinetis/nxp_k6x.dtsi:315 */
		gpioc: gpio@400ff080 {
			compatible = "nxp,kinetis-gpio"; /* in zephyr/dts/arm/nxp/kinetis/nxp_k6x.dtsi:316 */
			reg = < 0x400ff080 0x40 >;       /* in zephyr/dts/arm/nxp/kinetis/nxp_k6x.dtsi:318 */
			interrupts = < 0x3d 0x2 >;       /* in zephyr/dts/arm/nxp/kinetis/nxp_k6x.dtsi:319 */
			gpio-controller;                 /* in zephyr/dts/arm/nxp/kinetis/nxp_k6x.dtsi:320 */
			#gpio-cells = < 0x2 >;           /* in zephyr/dts/arm/nxp/kinetis/nxp_k6x.dtsi:321 */
			nxp,kinetis-port = < &portc >;   /* in zephyr/dts/arm/nxp/kinetis/nxp_k6x.dtsi:322 */
			status = "okay";                 /* in zephyr/boards/nxp/frdm_k64f/frdm_k64f.dts:230 */
			phandle = < 0x5 >;               /* in zephyr/boards/nxp/frdm_k64f/frdm_k64f.dts:153 */
		};

		/* node '/soc/gpio@400ff0c0' defined in zephyr/dts/arm/nxp/kinetis/nxp_k6x.dtsi:325 */
		gpiod: gpio@400ff0c0 {
			compatible = "nxp,kinetis-gpio"; /* in zephyr/dts/arm/nxp/kinetis/nxp_k6x.dtsi:326 */
			reg = < 0x400ff0c0 0x40 >;       /* in zephyr/dts/arm/nxp/kinetis/nxp_k6x.dtsi:328 */
			interrupts = < 0x3e 0x2 >;       /* in zephyr/dts/arm/nxp/kinetis/nxp_k6x.dtsi:329 */
			gpio-controller;                 /* in zephyr/dts/arm/nxp/kinetis/nxp_k6x.dtsi:330 */
			#gpio-cells = < 0x2 >;           /* in zephyr/dts/arm/nxp/kinetis/nxp_k6x.dtsi:331 */
			nxp,kinetis-port = < &portd >;   /* in zephyr/dts/arm/nxp/kinetis/nxp_k6x.dtsi:332 */
			status = "okay";                 /* in zephyr/boards/nxp/frdm_k64f/frdm_k64f.dts:234 */
			phandle = < 0x23 >;              /* in zephyr/boards/nxp/frdm_k64f/frdm_k64f.dts:80 */
		};

		/* node '/soc/gpio@400ff100' defined in zephyr/dts/arm/nxp/kinetis/nxp_k6x.dtsi:335 */
		gpioe: gpio@400ff100 {
			compatible = "nxp,kinetis-gpio"; /* in zephyr/dts/arm/nxp/kinetis/nxp_k6x.dtsi:336 */
			reg = < 0x400ff100 0x40 >;       /* in zephyr/dts/arm/nxp/kinetis/nxp_k6x.dtsi:338 */
			interrupts = < 0x3f 0x2 >;       /* in zephyr/dts/arm/nxp/kinetis/nxp_k6x.dtsi:339 */
			gpio-controller;                 /* in zephyr/dts/arm/nxp/kinetis/nxp_k6x.dtsi:340 */
			#gpio-cells = < 0x2 >;           /* in zephyr/dts/arm/nxp/kinetis/nxp_k6x.dtsi:341 */
			nxp,kinetis-port = < &porte >;   /* in zephyr/dts/arm/nxp/kinetis/nxp_k6x.dtsi:342 */
			status = "okay";                 /* in zephyr/boards/nxp/frdm_k64f/frdm_k64f.dts:238 */
			phandle = < 0x13 >;              /* in zephyr/boards/nxp/frdm_k64f/frdm_k64f.dts:168 */
		};

		/* node '/soc/spi@4002c000' defined in zephyr/dts/arm/nxp/kinetis/nxp_k6x.dtsi:345 */
		spi0: arduino_spi: spi@4002c000 {
			compatible = "nxp,dspi";                 /* in zephyr/dts/arm/nxp/kinetis/nxp_k6x.dtsi:346 */
			reg = < 0x4002c000 0x88 >;               /* in zephyr/dts/arm/nxp/kinetis/nxp_k6x.dtsi:347 */
			interrupts = < 0x1a 0x3 >;               /* in zephyr/dts/arm/nxp/kinetis/nxp_k6x.dtsi:348 */
			dmas = < &edma0 0x0 0xe >,
			       < &edma0 0x0 0xf >;               /* in zephyr/dts/arm/nxp/kinetis/nxp_k6x.dtsi:349 */
			dma-names = "rx",
			            "tx";                        /* in zephyr/dts/arm/nxp/kinetis/nxp_k6x.dtsi:350 */
			rx-fifo-size = < 0x4 >;                  /* in zephyr/dts/arm/nxp/kinetis/nxp_k6x.dtsi:351 */
			tx-fifo-size = < 0x4 >;                  /* in zephyr/dts/arm/nxp/kinetis/nxp_k6x.dtsi:352 */
			clocks = < &sim 0x81e30400 0x103c 0xc >; /* in zephyr/dts/arm/nxp/kinetis/nxp_k6x.dtsi:353 */
			#address-cells = < 0x1 >;                /* in zephyr/dts/arm/nxp/kinetis/nxp_k6x.dtsi:354 */
			#size-cells = < 0x0 >;                   /* in zephyr/dts/arm/nxp/kinetis/nxp_k6x.dtsi:355 */
			status = "okay";                         /* in zephyr/boards/nxp/frdm_k64f/frdm_k64f.dts:159 */
			pinctrl-0 = < &spi0_default >;           /* in zephyr/boards/nxp/frdm_k64f/frdm_k64f.dts:160 */
			pinctrl-names = "default";               /* in zephyr/boards/nxp/frdm_k64f/frdm_k64f.dts:161 */
			cs-gpios = < &adapter_1_mb1 0x2 0x1 >,
			           < &adapter_1_mb2 0x2 0x1 >;   /* in <RIGC_BUILD>/rig/rig-gen.overlay:26 */
			phandle = < 0x25 >;                      /* in btr-shields/boards/extend/nxp/frdm_k64f/arduino_r3_socket.dtsi:60 */

			/* node '/soc/spi@4002c000/eth@0' defined in <RIGC_BUILD>/rig/rig-gen.overlay:27 */
			eth_1_eth: eth@0 {
				compatible = "microchip,enc28j60";         /* in <RIGC_BUILD>/rig/rig-gen.overlay:28 */
				spi-max-frequency = < 0x1312d00 >;         /* in <RIGC_BUILD>/rig/rig-gen.overlay:29 */
				local-mac-address = [ 00 00 00 00 00 00 ]; /* in <RIGC_BUILD>/rig/rig-gen.overlay:30 */
				zephyr,random-mac-address;                 /* in <RIGC_BUILD>/rig/rig-gen.overlay:31 */
				reg = < 0x0 >;                             /* in <RIGC_BUILD>/rig/rig-gen.overlay:32 */
				int-gpios = < &adapter_1_mb1 0x7 0x1 >;    /* in <RIGC_BUILD>/rig/rig-gen.overlay:33 */
				status = "okay";                           /* in <RIGC_BUILD>/rig/rig-gen.overlay:34 */
			};

			/* node '/soc/spi@4002c000/eth@1' defined in <RIGC_BUILD>/rig/rig-gen.overlay:36 */
			eth_2_eth: eth@1 {
				compatible = "microchip,enc28j60";         /* in <RIGC_BUILD>/rig/rig-gen.overlay:37 */
				spi-max-frequency = < 0x1312d00 >;         /* in <RIGC_BUILD>/rig/rig-gen.overlay:38 */
				local-mac-address = [ 00 00 00 00 00 00 ]; /* in <RIGC_BUILD>/rig/rig-gen.overlay:39 */
				zephyr,random-mac-address;                 /* in <RIGC_BUILD>/rig/rig-gen.overlay:40 */
				reg = < 0x1 >;                             /* in <RIGC_BUILD>/rig/rig-gen.overlay:41 */
				int-gpios = < &adapter_1_mb2 0x7 0x1 >;    /* in <RIGC_BUILD>/rig/rig-gen.overlay:42 */
				status = "okay";                           /* in <RIGC_BUILD>/rig/rig-gen.overlay:43 */
			};
		};

		/* node '/soc/spi@4002d000' defined in zephyr/dts/arm/nxp/kinetis/nxp_k6x.dtsi:359 */
		spi1: spi@4002d000 {
			compatible = "nxp,dspi";                 /* in zephyr/dts/arm/nxp/kinetis/nxp_k6x.dtsi:360 */
			reg = < 0x4002d000 0x88 >;               /* in zephyr/dts/arm/nxp/kinetis/nxp_k6x.dtsi:361 */
			interrupts = < 0x1b 0x3 >;               /* in zephyr/dts/arm/nxp/kinetis/nxp_k6x.dtsi:362 */
			dmas = < &edma0 0x0 0x10 >,
			       < &edma0 0x0 0x10 >;              /* in zephyr/dts/arm/nxp/kinetis/nxp_k6x.dtsi:363 */
			dma-names = "rx",
			            "tx";                        /* in zephyr/dts/arm/nxp/kinetis/nxp_k6x.dtsi:364 */
			rx-fifo-size = < 0x1 >;                  /* in zephyr/dts/arm/nxp/kinetis/nxp_k6x.dtsi:365 */
			tx-fifo-size = < 0x1 >;                  /* in zephyr/dts/arm/nxp/kinetis/nxp_k6x.dtsi:366 */
			nxp,rx-tx-chn-share;                     /* in zephyr/dts/arm/nxp/kinetis/nxp_k6x.dtsi:367 */
			clocks = < &sim 0x81e34400 0x103c 0xd >; /* in zephyr/dts/arm/nxp/kinetis/nxp_k6x.dtsi:368 */
			#address-cells = < 0x1 >;                /* in zephyr/dts/arm/nxp/kinetis/nxp_k6x.dtsi:369 */
			#size-cells = < 0x0 >;                   /* in zephyr/dts/arm/nxp/kinetis/nxp_k6x.dtsi:370 */
			status = "okay";                         /* in zephyr/boards/nxp/frdm_k64f/frdm_k64f.dts:165 */
			pinctrl-0 = < &spi1_default >;           /* in zephyr/boards/nxp/frdm_k64f/frdm_k64f.dts:166 */
			pinctrl-names = "default";               /* in zephyr/boards/nxp/frdm_k64f/frdm_k64f.dts:167 */
			cs-gpios = < &gpioe 0x4 0x1 >;           /* in zephyr/boards/nxp/frdm_k64f/frdm_k64f.dts:168 */

			/* node '/soc/spi@4002d000/sdhc@0' defined in zephyr/boards/nxp/frdm_k64f/frdm_k64f.dts:170 */
			sdhc0: sdhc@0 {
				compatible = "zephyr,sdhc-spi-slot"; /* in zephyr/boards/nxp/frdm_k64f/frdm_k64f.dts:171 */
				reg = < 0x0 >;                       /* in zephyr/boards/nxp/frdm_k64f/frdm_k64f.dts:172 */
				status = "okay";                     /* in zephyr/boards/nxp/frdm_k64f/frdm_k64f.dts:173 */
				spi-max-frequency = < 0x16e3600 >;   /* in zephyr/boards/nxp/frdm_k64f/frdm_k64f.dts:181 */

				/* node '/soc/spi@4002d000/sdhc@0/sdmmc' defined in zephyr/boards/nxp/frdm_k64f/frdm_k64f.dts:175 */
				sdmmc {
					compatible = "zephyr,sdmmc-disk"; /* in zephyr/boards/nxp/frdm_k64f/frdm_k64f.dts:176 */
					disk-name = "SD";                 /* in zephyr/boards/nxp/frdm_k64f/frdm_k64f.dts:177 */
					status = "okay";                  /* in zephyr/boards/nxp/frdm_k64f/frdm_k64f.dts:178 */
				};
			};
		};

		/* node '/soc/spi@400ac000' defined in zephyr/dts/arm/nxp/kinetis/nxp_k6x.dtsi:374 */
		spi2: spi@400ac000 {
			compatible = "nxp,dspi";                 /* in zephyr/dts/arm/nxp/kinetis/nxp_k6x.dtsi:375 */
			reg = < 0x400ac000 0x88 >;               /* in zephyr/dts/arm/nxp/kinetis/nxp_k6x.dtsi:376 */
			interrupts = < 0x41 0x3 >;               /* in zephyr/dts/arm/nxp/kinetis/nxp_k6x.dtsi:377 */
			dmas = < &edma0 0x0 0x26 >,
			       < &edma0 0x0 0x27 >;              /* in zephyr/dts/arm/nxp/kinetis/nxp_k6x.dtsi:378 */
			dma-names = "rx",
			            "tx";                        /* in zephyr/dts/arm/nxp/kinetis/nxp_k6x.dtsi:379 */
			rx-fifo-size = < 0x1 >;                  /* in zephyr/dts/arm/nxp/kinetis/nxp_k6x.dtsi:380 */
			tx-fifo-size = < 0x1 >;                  /* in zephyr/dts/arm/nxp/kinetis/nxp_k6x.dtsi:381 */
			nxp,rx-tx-chn-share;                     /* in zephyr/dts/arm/nxp/kinetis/nxp_k6x.dtsi:382 */
			clocks = < &sim 0x81830400 0x1030 0xc >; /* in zephyr/dts/arm/nxp/kinetis/nxp_k6x.dtsi:383 */
			#address-cells = < 0x1 >;                /* in zephyr/dts/arm/nxp/kinetis/nxp_k6x.dtsi:384 */
			#size-cells = < 0x0 >;                   /* in zephyr/dts/arm/nxp/kinetis/nxp_k6x.dtsi:385 */
			status = "disabled";                     /* in zephyr/dts/arm/nxp/kinetis/nxp_k6x.dtsi:386 */
		};

		/* node '/soc/watchdog@40052000' defined in zephyr/dts/arm/nxp/kinetis/nxp_k6x.dtsi:389 */
		wdog: watchdog@40052000 {
			compatible = "nxp,kinetis-wdog";  /* in zephyr/dts/arm/nxp/kinetis/nxp_k6x.dtsi:390 */
			reg = < 0x40052000 0x10 >;        /* in zephyr/dts/arm/nxp/kinetis/nxp_k6x.dtsi:391 */
			interrupts = < 0x16 0x0 >;        /* in zephyr/dts/arm/nxp/kinetis/nxp_k6x.dtsi:392 */
			clocks = < &sim 0x2600 0x0 0x0 >; /* in zephyr/dts/arm/nxp/kinetis/nxp_k6x.dtsi:393 */
		};

		/* node '/soc/ftm@40038000' defined in zephyr/dts/arm/nxp/kinetis/nxp_k6x.dtsi:396 */
		ftm0: ftm@40038000 {
			reg = < 0x40038000 0x98 >;     /* in zephyr/dts/arm/nxp/kinetis/nxp_k6x.dtsi:398 */
			interrupts = < 0x2a 0x0 >;     /* in zephyr/dts/arm/nxp/kinetis/nxp_k6x.dtsi:399 */
			clocks = < &mcg 0x0 >;         /* in zephyr/dts/arm/nxp/kinetis/nxp_k6x.dtsi:400 */
			prescaler = < 0x10 >;          /* in zephyr/dts/arm/nxp/kinetis/nxp_k6x.dtsi:401 */
			status = "okay";               /* in zephyr/boards/nxp/frdm_k64f/frdm_k64f.dts:186 */
			compatible = "nxp,ftm-pwm";    /* in zephyr/boards/nxp/frdm_k64f/frdm_k64f.dts:187 */
			#pwm-cells = < 0x3 >;          /* in zephyr/boards/nxp/frdm_k64f/frdm_k64f.dts:188 */
			pinctrl-0 = < &ftm0_default >; /* in zephyr/boards/nxp/frdm_k64f/frdm_k64f.dts:189 */
			pinctrl-names = "default";     /* in zephyr/boards/nxp/frdm_k64f/frdm_k64f.dts:190 */
			clock-source = "fixed";        /* in zephyr/boards/nxp/frdm_k64f/frdm_k64f.dts:191 */
		};

		/* node '/soc/ftm@40039000' defined in zephyr/dts/arm/nxp/kinetis/nxp_k6x.dtsi:405 */
		ftm1: ftm@40039000 {
			compatible = "nxp,ftm";    /* in zephyr/dts/arm/nxp/kinetis/nxp_k6x.dtsi:406 */
			reg = < 0x40039000 0x98 >; /* in zephyr/dts/arm/nxp/kinetis/nxp_k6x.dtsi:407 */
			interrupts = < 0x2b 0x0 >; /* in zephyr/dts/arm/nxp/kinetis/nxp_k6x.dtsi:408 */
			clocks = < &mcg 0x0 >;     /* in zephyr/dts/arm/nxp/kinetis/nxp_k6x.dtsi:409 */
			prescaler = < 0x10 >;      /* in zephyr/dts/arm/nxp/kinetis/nxp_k6x.dtsi:410 */
			status = "disabled";       /* in zephyr/dts/arm/nxp/kinetis/nxp_k6x.dtsi:411 */
		};

		/* node '/soc/ftm@4003a000' defined in zephyr/dts/arm/nxp/kinetis/nxp_k6x.dtsi:414 */
		ftm2: ftm@4003a000 {
			compatible = "nxp,ftm";    /* in zephyr/dts/arm/nxp/kinetis/nxp_k6x.dtsi:415 */
			reg = < 0x4003a000 0x98 >; /* in zephyr/dts/arm/nxp/kinetis/nxp_k6x.dtsi:416 */
			interrupts = < 0x2c 0x0 >; /* in zephyr/dts/arm/nxp/kinetis/nxp_k6x.dtsi:417 */
			clocks = < &mcg 0x0 >;     /* in zephyr/dts/arm/nxp/kinetis/nxp_k6x.dtsi:418 */
			prescaler = < 0x10 >;      /* in zephyr/dts/arm/nxp/kinetis/nxp_k6x.dtsi:419 */
			status = "disabled";       /* in zephyr/dts/arm/nxp/kinetis/nxp_k6x.dtsi:420 */
		};

		/* node '/soc/ftm@400b9000' defined in zephyr/dts/arm/nxp/kinetis/nxp_k6x.dtsi:423 */
		ftm3: ftm@400b9000 {
			reg = < 0x400b9000 0x98 >;     /* in zephyr/dts/arm/nxp/kinetis/nxp_k6x.dtsi:425 */
			interrupts = < 0x47 0x0 >;     /* in zephyr/dts/arm/nxp/kinetis/nxp_k6x.dtsi:426 */
			clocks = < &mcg 0x0 >;         /* in zephyr/dts/arm/nxp/kinetis/nxp_k6x.dtsi:427 */
			prescaler = < 0x10 >;          /* in zephyr/dts/arm/nxp/kinetis/nxp_k6x.dtsi:428 */
			status = "okay";               /* in zephyr/boards/nxp/frdm_k64f/frdm_k64f.dts:195 */
			compatible = "nxp,ftm-pwm";    /* in zephyr/boards/nxp/frdm_k64f/frdm_k64f.dts:196 */
			#pwm-cells = < 0x3 >;          /* in zephyr/boards/nxp/frdm_k64f/frdm_k64f.dts:197 */
			pinctrl-0 = < &ftm3_default >; /* in zephyr/boards/nxp/frdm_k64f/frdm_k64f.dts:198 */
			pinctrl-names = "default";     /* in zephyr/boards/nxp/frdm_k64f/frdm_k64f.dts:199 */
			clock-source = "fixed";        /* in zephyr/boards/nxp/frdm_k64f/frdm_k64f.dts:200 */
		};

		/* node '/soc/adc@4003b000' defined in zephyr/dts/arm/nxp/kinetis/nxp_k6x.dtsi:432 */
		adc0: adc@4003b000 {
			compatible = "nxp,kinetis-adc16";    /* in zephyr/dts/arm/nxp/kinetis/nxp_k6x.dtsi:433 */
			reg = < 0x4003b000 0x70 >;           /* in zephyr/dts/arm/nxp/kinetis/nxp_k6x.dtsi:434 */
			clocks = < &sim 0x3ce00 0x0 0xf >,
			         < &sim 0x380e00 0x7 0x80 >; /* in zephyr/dts/arm/nxp/kinetis/nxp_k6x.dtsi:435 */
			dmas = < &edma0 0x0 0x28 >;          /* in zephyr/dts/arm/nxp/kinetis/nxp_k6x.dtsi:437 */
			dma-names = "adc0";                  /* in zephyr/dts/arm/nxp/kinetis/nxp_k6x.dtsi:438 */
			clk-source = < 0x0 >;                /* in zephyr/dts/arm/nxp/kinetis/nxp_k6x.dtsi:439 */
			interrupts = < 0x27 0x0 >;           /* in zephyr/dts/arm/nxp/kinetis/nxp_k6x.dtsi:440 */
			#io-channel-cells = < 0x1 >;         /* in zephyr/dts/arm/nxp/kinetis/nxp_k6x.dtsi:442 */
			status = "okay";                     /* in zephyr/boards/nxp/frdm_k64f/frdm_k64f.dts:125 */
			pinctrl-0 = < &adc0_default >;       /* in zephyr/boards/nxp/frdm_k64f/frdm_k64f.dts:126 */
			pinctrl-names = "default";           /* in zephyr/boards/nxp/frdm_k64f/frdm_k64f.dts:127 */
			phandle = < 0x1f >;                  /* in zephyr/dts/arm/nxp/kinetis/nxp_k6x.dtsi:59 */
		};

		/* node '/soc/adc@400bb000' defined in zephyr/dts/arm/nxp/kinetis/nxp_k6x.dtsi:445 */
		adc1: adc@400bb000 {
			compatible = "nxp,kinetis-adc16";      /* in zephyr/dts/arm/nxp/kinetis/nxp_k6x.dtsi:446 */
			reg = < 0x400bb000 0x70 >;             /* in zephyr/dts/arm/nxp/kinetis/nxp_k6x.dtsi:447 */
			clocks = < &sim 0x400e00 0x8 0xf00 >,
			         < &sim 0x780e00 0xf 0x8000 >; /* in zephyr/dts/arm/nxp/kinetis/nxp_k6x.dtsi:448 */
			dmas = < &edma0 0x0 0x29 >;            /* in zephyr/dts/arm/nxp/kinetis/nxp_k6x.dtsi:450 */
			dma-names = "adc1";                    /* in zephyr/dts/arm/nxp/kinetis/nxp_k6x.dtsi:451 */
			clk-source = < 0x0 >;                  /* in zephyr/dts/arm/nxp/kinetis/nxp_k6x.dtsi:452 */
			interrupts = < 0x49 0x0 >;             /* in zephyr/dts/arm/nxp/kinetis/nxp_k6x.dtsi:453 */
			#io-channel-cells = < 0x1 >;           /* in zephyr/dts/arm/nxp/kinetis/nxp_k6x.dtsi:455 */
			status = "okay";                       /* in zephyr/boards/nxp/frdm_k64f/frdm_k64f.dts:131 */
			pinctrl-0 = < &adc1_default >;         /* in zephyr/boards/nxp/frdm_k64f/frdm_k64f.dts:132 */
			pinctrl-names = "default";             /* in zephyr/boards/nxp/frdm_k64f/frdm_k64f.dts:133 */
			phandle = < 0x20 >;                    /* in zephyr/dts/arm/nxp/kinetis/nxp_k6x.dtsi:70 */
		};

		/* node '/soc/dac@400cc000' defined in zephyr/dts/arm/nxp/kinetis/nxp_k6x.dtsi:458 */
		dac0: dac@400cc000 {
			compatible = "nxp,kinetis-dac"; /* in zephyr/dts/arm/nxp/kinetis/nxp_k6x.dtsi:459 */
			reg = < 0x400cc000 0x1000 >;    /* in zephyr/dts/arm/nxp/kinetis/nxp_k6x.dtsi:460 */
			interrupts = < 0x38 0x0 >;      /* in zephyr/dts/arm/nxp/kinetis/nxp_k6x.dtsi:461 */
			#io-channel-cells = < 0x1 >;    /* in zephyr/dts/arm/nxp/kinetis/nxp_k6x.dtsi:464 */
			status = "okay";                /* in zephyr/boards/nxp/frdm_k64f/frdm_k64f.dts:141 */
			voltage-reference = < 0x2 >;    /* in zephyr/boards/nxp/frdm_k64f/frdm_k64f.dts:142 */
		};

		/* node '/soc/dac@400cd000' defined in zephyr/dts/arm/nxp/kinetis/nxp_k6x.dtsi:467 */
		dac1: dac@400cd000 {
			compatible = "nxp,kinetis-dac"; /* in zephyr/dts/arm/nxp/kinetis/nxp_k6x.dtsi:468 */
			reg = < 0x400cd000 0x1000 >;    /* in zephyr/dts/arm/nxp/kinetis/nxp_k6x.dtsi:469 */
			interrupts = < 0x48 0x0 >;      /* in zephyr/dts/arm/nxp/kinetis/nxp_k6x.dtsi:470 */
			voltage-reference = < 0x1 >;    /* in zephyr/dts/arm/nxp/kinetis/nxp_k6x.dtsi:471 */
			status = "disabled";            /* in zephyr/dts/arm/nxp/kinetis/nxp_k6x.dtsi:472 */
			#io-channel-cells = < 0x1 >;    /* in zephyr/dts/arm/nxp/kinetis/nxp_k6x.dtsi:473 */
		};

		/* node '/soc/usbd@40072000' defined in zephyr/dts/arm/nxp/kinetis/nxp_k6x.dtsi:476 */
		usbotg: zephyr_udc0: usbd@40072000 {
			reg = < 0x40072000 0x1000 >;     /* in zephyr/dts/arm/nxp/kinetis/nxp_k6x.dtsi:478 */
			interrupts = < 0x35 0x1 >;       /* in zephyr/dts/arm/nxp/kinetis/nxp_k6x.dtsi:479 */
			interrupt-names = "usb_otg";     /* in zephyr/dts/arm/nxp/kinetis/nxp_k6x.dtsi:480 */
			compatible = "nxp,kinetis-usbd"; /* in zephyr/boards/nxp/frdm_k64f/frdm_k64f.dts:216 */
			status = "okay";                 /* in zephyr/boards/nxp/frdm_k64f/frdm_k64f.dts:217 */
			num-bidir-endpoints = < 0x8 >;   /* in zephyr/boards/nxp/frdm_k64f/frdm_k64f.dts:218 */
		};

		/* node '/soc/ethernet@400c0000' defined in zephyr/dts/arm/nxp/kinetis/nxp_k6x.dtsi:485 */
		enet: ethernet@400c0000 {
			compatible = "nxp,enet";                 /* in zephyr/dts/arm/nxp/kinetis/nxp_k6x.dtsi:486 */
			reg = < 0x400c0000 0x620 >;              /* in zephyr/dts/arm/nxp/kinetis/nxp_k6x.dtsi:487 */
			clocks = < &sim 0x81600000 0x102c 0x0 >; /* in zephyr/dts/arm/nxp/kinetis/nxp_k6x.dtsi:488 */
			status = "okay";                         /* in zephyr/boards/nxp/frdm_k64f/frdm_k64f.dts:275 */
			pinctrl-0 = < &pinmux_enet >;            /* in zephyr/boards/nxp/frdm_k64f/frdm_k64f.dts:276 */
			pinctrl-names = "default";               /* in zephyr/boards/nxp/frdm_k64f/frdm_k64f.dts:277 */

			/* node '/soc/ethernet@400c0000/ethernet' defined in zephyr/dts/arm/nxp/kinetis/nxp_k6x.dtsi:490 */
			enet_mac: ethernet {
				compatible = "nxp,enet-mac";     /* in zephyr/dts/arm/nxp/kinetis/nxp_k6x.dtsi:491 */
				interrupts = < 0x53 0x0 >,
				             < 0x54 0x0 >,
				             < 0x55 0x0 >;       /* in zephyr/dts/arm/nxp/kinetis/nxp_k6x.dtsi:492 */
				interrupt-names = "TX",
				                  "RX",
				                  "ERR";         /* in zephyr/dts/arm/nxp/kinetis/nxp_k6x.dtsi:493 */
				nxp,mdio = < &enet_mdio >;       /* in zephyr/dts/arm/nxp/kinetis/nxp_k6x.dtsi:494 */
				ptp-clock = < &enet_ptp_clock >; /* in zephyr/dts/arm/nxp/kinetis/nxp_k6x.dtsi:495 */
				status = "okay";                 /* in zephyr/boards/nxp/frdm_k64f/frdm_k64f.dts:281 */
				phy-handle = < &phy >;           /* in zephyr/boards/nxp/frdm_k64f/frdm_k64f.dts:282 */
				zephyr,random-mac-address;       /* in zephyr/boards/nxp/frdm_k64f/frdm_k64f.dts:283 */
				phy-connection-type = "rmii";    /* in zephyr/boards/nxp/frdm_k64f/frdm_k64f.dts:284 */
			};

			/* node '/soc/ethernet@400c0000/mdio' defined in zephyr/dts/arm/nxp/kinetis/nxp_k6x.dtsi:500 */
			enet_mdio: mdio {
				compatible = "nxp,enet-mdio";      /* in zephyr/dts/arm/nxp/kinetis/nxp_k6x.dtsi:501 */
				#address-cells = < 0x1 >;          /* in zephyr/dts/arm/nxp/kinetis/nxp_k6x.dtsi:503 */
				#size-cells = < 0x0 >;             /* in zephyr/dts/arm/nxp/kinetis/nxp_k6x.dtsi:504 */
				status = "okay";                   /* in zephyr/boards/nxp/frdm_k64f/frdm_k64f.dts:288 */
				pinctrl-0 = < &pinmux_enet_mdio >; /* in zephyr/boards/nxp/frdm_k64f/frdm_k64f.dts:289 */
				pinctrl-names = "default";         /* in zephyr/boards/nxp/frdm_k64f/frdm_k64f.dts:290 */
				phandle = < 0x19 >;                /* in zephyr/dts/arm/nxp/kinetis/nxp_k6x.dtsi:494 */

				/* node '/soc/ethernet@400c0000/mdio/phy@0' defined in zephyr/boards/nxp/frdm_k64f/frdm_k64f.dts:292 */
				phy: phy@0 {
					compatible = "microchip,ksz8081";        /* in zephyr/boards/nxp/frdm_k64f/frdm_k64f.dts:293 */
					reg = < 0x0 >;                           /* in zephyr/boards/nxp/frdm_k64f/frdm_k64f.dts:294 */
					status = "okay";                         /* in zephyr/boards/nxp/frdm_k64f/frdm_k64f.dts:295 */
					microchip,interface-type = "rmii-25MHz"; /* in zephyr/boards/nxp/frdm_k64f/frdm_k64f.dts:296 */
					phandle = < 0x1b >;                      /* in zephyr/boards/nxp/frdm_k64f/frdm_k64f.dts:282 */
				};
			};

			/* node '/soc/ethernet@400c0000/ptp_clock' defined in zephyr/dts/arm/nxp/kinetis/nxp_k6x.dtsi:507 */
			enet_ptp_clock: ptp_clock {
				compatible = "nxp,enet-ptp-clock"; /* in zephyr/dts/arm/nxp/kinetis/nxp_k6x.dtsi:508 */
				interrupts = < 0x52 0x0 >;         /* in zephyr/dts/arm/nxp/kinetis/nxp_k6x.dtsi:509 */
				interrupt-names = "IEEE1588_TMR";  /* in zephyr/dts/arm/nxp/kinetis/nxp_k6x.dtsi:510 */
				clocks = < &sim 0x1000 0x0 0x0 >;  /* in zephyr/dts/arm/nxp/kinetis/nxp_k6x.dtsi:511 */
				status = "okay";                   /* in zephyr/boards/nxp/frdm_k64f/frdm_k64f.dts:301 */
				pinctrl-0 = < &pinmux_ptp >;       /* in zephyr/boards/nxp/frdm_k64f/frdm_k64f.dts:302 */
				pinctrl-names = "default";         /* in zephyr/boards/nxp/frdm_k64f/frdm_k64f.dts:303 */
				phandle = < 0x1a >;                /* in zephyr/dts/arm/nxp/kinetis/nxp_k6x.dtsi:495 */
			};
		};

		/* node '/soc/random@40029000' defined in zephyr/dts/arm/nxp/kinetis/nxp_k6x.dtsi:517 */
		rnga: random@40029000 {
			compatible = "nxp,kinetis-rnga"; /* in zephyr/dts/arm/nxp/kinetis/nxp_k6x.dtsi:518 */
			reg = < 0x40029000 0x1000 >;     /* in zephyr/dts/arm/nxp/kinetis/nxp_k6x.dtsi:519 */
			status = "okay";                 /* in zephyr/dts/arm/nxp/kinetis/nxp_k6x.dtsi:520 */
			interrupts = < 0x17 0x0 >;       /* in zephyr/dts/arm/nxp/kinetis/nxp_k6x.dtsi:521 */
		};

		/* node '/soc/can@40024000' defined in zephyr/dts/arm/nxp/kinetis/nxp_k6x.dtsi:524 */
		flexcan0: can@40024000 {
			compatible = "nxp,flexcan";              /* in zephyr/dts/arm/nxp/kinetis/nxp_k6x.dtsi:525 */
			reg = < 0x40024000 0x1000 >;             /* in zephyr/dts/arm/nxp/kinetis/nxp_k6x.dtsi:526 */
			interrupts = < 0x4b 0x0 >,
			             < 0x4c 0x0 >,
			             < 0x4d 0x0 >,
			             < 0x4e 0x0 >,
			             < 0x4f 0x0 >,
			             < 0x50 0x0 >;               /* in zephyr/dts/arm/nxp/kinetis/nxp_k6x.dtsi:527 */
			interrupt-names = "mb-0-15",
			                  "bus-off",
			                  "error",
			                  "tx-warning",
			                  "rx-warning",
			                  "wake-up";             /* in zephyr/dts/arm/nxp/kinetis/nxp_k6x.dtsi:528 */
			clocks = < &sim 0x81e11000 0x103c 0x4 >,
			         < &sim 0x81e10400 0x103c 0x4 >; /* in zephyr/dts/arm/nxp/kinetis/nxp_k6x.dtsi:530 */
			clock-names = "clksrc0",
			              "clksrc1";                 /* in zephyr/dts/arm/nxp/kinetis/nxp_k6x.dtsi:532 */
			clk-source = < 0x1 >;                    /* in zephyr/dts/arm/nxp/kinetis/nxp_k6x.dtsi:533 */
			number-of-mb = < 0x10 >;                 /* in zephyr/dts/arm/nxp/kinetis/nxp_k6x.dtsi:534 */
			status = "okay";                         /* in zephyr/boards/nxp/frdm_k64f/frdm_k64f.dts:307 */
			pinctrl-0 = < &flexcan0_default >;       /* in zephyr/boards/nxp/frdm_k64f/frdm_k64f.dts:308 */
			pinctrl-names = "default";               /* in zephyr/boards/nxp/frdm_k64f/frdm_k64f.dts:309 */
		};

		/* node '/soc/dma-controller@40008000' defined in zephyr/dts/arm/nxp/kinetis/nxp_k6x.dtsi:538 */
		edma0: dma-controller@40008000 {
			#dma-cells = < 0x2 >;                    /* in zephyr/dts/arm/nxp/kinetis/nxp_k6x.dtsi:539 */
			compatible = "nxp,mcux-edma";            /* in zephyr/dts/arm/nxp/kinetis/nxp_k6x.dtsi:540 */
			nxp,version = < 0x2 >;                   /* in zephyr/dts/arm/nxp/kinetis/nxp_k6x.dtsi:541 */
			dma-channels = < 0x10 >;                 /* in zephyr/dts/arm/nxp/kinetis/nxp_k6x.dtsi:542 */
			dma-requests = < 0x40 >;                 /* in zephyr/dts/arm/nxp/kinetis/nxp_k6x.dtsi:543 */
			nxp,mem2mem;                             /* in zephyr/dts/arm/nxp/kinetis/nxp_k6x.dtsi:544 */
			reg = < 0x40008000 0x1000 >,
			      < 0x40021000 0x1000 >;             /* in zephyr/dts/arm/nxp/kinetis/nxp_k6x.dtsi:545 */
			interrupts = < 0x0 0x0 >,
			             < 0x1 0x0 >,
			             < 0x2 0x0 >,
			             < 0x3 0x0 >,
			             < 0x4 0x0 >,
			             < 0x5 0x0 >,
			             < 0x6 0x0 >,
			             < 0x7 0x0 >,
			             < 0x8 0x0 >,
			             < 0x9 0x0 >,
			             < 0xa 0x0 >,
			             < 0xb 0x0 >,
			             < 0xc 0x0 >,
			             < 0xd 0x0 >,
			             < 0xe 0x0 >,
			             < 0xf 0x0 >,
			             < 0x10 0x0 >;               /* in zephyr/dts/arm/nxp/kinetis/nxp_k6x.dtsi:547 */
			clocks = < &sim 0x82004000 0x1040 0x1 >,
			         < &sim 0x81e04400 0x103c 0x1 >; /* in zephyr/dts/arm/nxp/kinetis/nxp_k6x.dtsi:552 */
			status = "okay";                         /* in zephyr/boards/nxp/frdm_k64f/frdm_k64f.dts:313 */
			phandle = < 0xe >;                       /* in zephyr/dts/arm/nxp/kinetis/nxp_k6x.dtsi:349 */
		};

		/* node '/soc/pit@40037000' defined in zephyr/dts/arm/nxp/kinetis/nxp_k6x.dtsi:558 */
		pit0: pit@40037000 {
			compatible = "nxp,pit";                   /* in zephyr/dts/arm/nxp/kinetis/nxp_k6x.dtsi:559 */
			reg = < 0x40037000 0x1000 >;              /* in zephyr/dts/arm/nxp/kinetis/nxp_k6x.dtsi:560 */
			clocks = < &sim 0x81e5c400 0x103c 0x17 >; /* in zephyr/dts/arm/nxp/kinetis/nxp_k6x.dtsi:561 */
			max-load-value = < 0xffffffff >;          /* in zephyr/dts/arm/nxp/kinetis/nxp_k6x.dtsi:563 */
			#address-cells = < 0x1 >;                 /* in zephyr/dts/arm/nxp/kinetis/nxp_k6x.dtsi:564 */
			#size-cells = < 0x0 >;                    /* in zephyr/dts/arm/nxp/kinetis/nxp_k6x.dtsi:565 */
			status = "okay";                          /* in zephyr/boards/nxp/frdm_k64f/frdm_k64f.dts:317 */

			/* node '/soc/pit@40037000/pit0_channel@0' defined in zephyr/dts/arm/nxp/kinetis/nxp_k6x.dtsi:567 */
			pit0_channel0: pit0_channel@0 {
				compatible = "nxp,pit-channel"; /* in zephyr/dts/arm/nxp/kinetis/nxp_k6x.dtsi:568 */
				reg = < 0x0 >;                  /* in zephyr/dts/arm/nxp/kinetis/nxp_k6x.dtsi:569 */
				interrupts = < 0x30 0x0 >;      /* in zephyr/dts/arm/nxp/kinetis/nxp_k6x.dtsi:570 */
				status = "disabled";            /* in zephyr/dts/arm/nxp/kinetis/nxp_k6x.dtsi:571 */
			};

			/* node '/soc/pit@40037000/pit0_channel@1' defined in zephyr/dts/arm/nxp/kinetis/nxp_k6x.dtsi:574 */
			pit0_channel1: pit0_channel@1 {
				compatible = "nxp,pit-channel"; /* in zephyr/dts/arm/nxp/kinetis/nxp_k6x.dtsi:575 */
				reg = < 0x1 >;                  /* in zephyr/dts/arm/nxp/kinetis/nxp_k6x.dtsi:576 */
				interrupts = < 0x31 0x0 >;      /* in zephyr/dts/arm/nxp/kinetis/nxp_k6x.dtsi:577 */
				status = "disabled";            /* in zephyr/dts/arm/nxp/kinetis/nxp_k6x.dtsi:578 */
			};

			/* node '/soc/pit@40037000/pit0_channel@2' defined in zephyr/dts/arm/nxp/kinetis/nxp_k6x.dtsi:581 */
			pit0_channel2: pit0_channel@2 {
				compatible = "nxp,pit-channel"; /* in zephyr/dts/arm/nxp/kinetis/nxp_k6x.dtsi:582 */
				reg = < 0x2 >;                  /* in zephyr/dts/arm/nxp/kinetis/nxp_k6x.dtsi:583 */
				interrupts = < 0x32 0x0 >;      /* in zephyr/dts/arm/nxp/kinetis/nxp_k6x.dtsi:584 */
				status = "disabled";            /* in zephyr/dts/arm/nxp/kinetis/nxp_k6x.dtsi:585 */
			};

			/* node '/soc/pit@40037000/pit0_channel@3' defined in zephyr/dts/arm/nxp/kinetis/nxp_k6x.dtsi:588 */
			pit0_channel3: pit0_channel@3 {
				compatible = "nxp,pit-channel"; /* in zephyr/dts/arm/nxp/kinetis/nxp_k6x.dtsi:589 */
				reg = < 0x3 >;                  /* in zephyr/dts/arm/nxp/kinetis/nxp_k6x.dtsi:590 */
				interrupts = < 0x33 0x0 >;      /* in zephyr/dts/arm/nxp/kinetis/nxp_k6x.dtsi:591 */
				status = "disabled";            /* in zephyr/dts/arm/nxp/kinetis/nxp_k6x.dtsi:592 */
			};
		};
	};

	/* node '/cpus' defined in zephyr/dts/arm/nxp/kinetis/nxp_k6x.dtsi:26 */
	cpus {
		#address-cells = < 0x1 >; /* in zephyr/dts/arm/nxp/kinetis/nxp_k6x.dtsi:27 */
		#size-cells = < 0x0 >;    /* in zephyr/dts/arm/nxp/kinetis/nxp_k6x.dtsi:28 */

		/* node '/cpus/cpu@0' defined in zephyr/dts/arm/nxp/kinetis/nxp_k6x.dtsi:30 */
		cpu0: cpu@0 {
			device_type = "cpu";             /* in zephyr/dts/arm/nxp/kinetis/nxp_k6x.dtsi:31 */
			compatible = "arm,cortex-m4f";   /* in zephyr/dts/arm/nxp/kinetis/nxp_k6x.dtsi:32 */
			reg = < 0x0 >;                   /* in zephyr/dts/arm/nxp/kinetis/nxp_k6x.dtsi:33 */
			clock-frequency = < 0x7270e00 >; /* in zephyr/boards/nxp/frdm_k64f/frdm_k64f.dts:121 */
		};
	};

	/* node '/memory@1fff0000' defined in zephyr/dts/arm/nxp/kinetis/nxp_k6x.dtsi:46 */
	sram_l: memory@1fff0000 {
		compatible = "zephyr,memory-region",
		             "mmio-sram";            /* in zephyr/dts/arm/nxp/kinetis/nxp_k6x.dtsi:47 */
		reg = < 0x1fff0000 0x10000 >;        /* in zephyr/dts/arm/nxp/kinetis/nxp_k6x.dtsi:48 */
		zephyr,memory-region = "SRAML";      /* in zephyr/dts/arm/nxp/kinetis/nxp_k6x.dtsi:49 */
	};

	/* node '/memory@20000000' defined in zephyr/dts/arm/nxp/kinetis/nxp_k6x.dtsi:52 */
	sram0: memory@20000000 {
		compatible = "mmio-sram";     /* in zephyr/dts/arm/nxp/kinetis/nxp_k6x.dtsi:53 */
		reg = < 0x20000000 0x30000 >; /* in zephyr/dts/arm/nxp/kinetis/nxp_k6x.dtsi:54 */
	};

	/* node '/temp0' defined in zephyr/dts/arm/nxp/kinetis/nxp_k6x.dtsi:57 */
	temp0: temp0 {
		compatible = "nxp,kinetis-temperature"; /* in zephyr/dts/arm/nxp/kinetis/nxp_k6x.dtsi:58 */
		io-channels = < &adc0 0x1a >,
		              < &adc0 0x1b >;           /* in zephyr/dts/arm/nxp/kinetis/nxp_k6x.dtsi:59 */
		io-channel-names = "SENSOR",
		                   "BANDGAP";           /* in zephyr/dts/arm/nxp/kinetis/nxp_k6x.dtsi:60 */
		bandgap-voltage = < 0xf4240 >;          /* in zephyr/dts/arm/nxp/kinetis/nxp_k6x.dtsi:61 */
		vtemp25 = < 0xaece0 >;                  /* in zephyr/dts/arm/nxp/kinetis/nxp_k6x.dtsi:62 */
		sensor-slope-cold = < 0x654 >;          /* in zephyr/dts/arm/nxp/kinetis/nxp_k6x.dtsi:63 */
		sensor-slope-hot = < 0x654 >;           /* in zephyr/dts/arm/nxp/kinetis/nxp_k6x.dtsi:64 */
		status = "disabled";                    /* in zephyr/dts/arm/nxp/kinetis/nxp_k6x.dtsi:65 */
	};

	/* node '/temp1' defined in zephyr/dts/arm/nxp/kinetis/nxp_k6x.dtsi:68 */
	temp1: temp1 {
		compatible = "nxp,kinetis-temperature"; /* in zephyr/dts/arm/nxp/kinetis/nxp_k6x.dtsi:69 */
		io-channels = < &adc1 0x1a >,
		              < &adc1 0x1b >;           /* in zephyr/dts/arm/nxp/kinetis/nxp_k6x.dtsi:70 */
		io-channel-names = "SENSOR",
		                   "BANDGAP";           /* in zephyr/dts/arm/nxp/kinetis/nxp_k6x.dtsi:71 */
		bandgap-voltage = < 0xf4240 >;          /* in zephyr/dts/arm/nxp/kinetis/nxp_k6x.dtsi:72 */
		vtemp25 = < 0xaece0 >;                  /* in zephyr/dts/arm/nxp/kinetis/nxp_k6x.dtsi:73 */
		sensor-slope-cold = < 0x654 >;          /* in zephyr/dts/arm/nxp/kinetis/nxp_k6x.dtsi:74 */
		sensor-slope-hot = < 0x654 >;           /* in zephyr/dts/arm/nxp/kinetis/nxp_k6x.dtsi:75 */
		status = "okay";                        /* in zephyr/boards/nxp/frdm_k64f/frdm_k64f.dts:137 */
	};

	/* node '/pinctrl' defined in zephyr/dts/arm/nxp/kinetis/nxp_k6x.dtsi:80 */
	pinctrl: pinctrl {
		compatible = "nxp,port-pinctrl"; /* in zephyr/dts/arm/nxp/kinetis/nxp_k6x.dtsi:81 */
		status = "okay";                 /* in zephyr/dts/arm/nxp/kinetis/nxp_k6x.dtsi:82 */

		/* node '/pinctrl/adc0_default' defined in zephyr/boards/nxp/frdm_k64f/frdm_k64f-pinctrl.dtsi:12 */
		adc0_default: adc0_default {
			phandle = < 0x16 >; /* in zephyr/boards/nxp/frdm_k64f/frdm_k64f.dts:126 */

			/* node '/pinctrl/adc0_default/group0' defined in zephyr/boards/nxp/frdm_k64f/frdm_k64f-pinctrl.dtsi:13 */
			group0 {
				pinmux = < 0x20000000 >; /* in zephyr/boards/nxp/frdm_k64f/frdm_k64f-pinctrl.dtsi:14 */
				drive-strength = "low";  /* in zephyr/boards/nxp/frdm_k64f/frdm_k64f-pinctrl.dtsi:15 */
				slew-rate = "fast";      /* in zephyr/boards/nxp/frdm_k64f/frdm_k64f-pinctrl.dtsi:16 */
			};
		};

		/* node '/pinctrl/adc1_default' defined in zephyr/boards/nxp/frdm_k64f/frdm_k64f-pinctrl.dtsi:20 */
		adc1_default: adc1_default {
			phandle = < 0x17 >; /* in zephyr/boards/nxp/frdm_k64f/frdm_k64f.dts:132 */

			/* node '/pinctrl/adc1_default/group0' defined in zephyr/boards/nxp/frdm_k64f/frdm_k64f-pinctrl.dtsi:21 */
			group0 {
				pinmux = < 0x12800000 >; /* in zephyr/boards/nxp/frdm_k64f/frdm_k64f-pinctrl.dtsi:22 */
				drive-strength = "low";  /* in zephyr/boards/nxp/frdm_k64f/frdm_k64f-pinctrl.dtsi:23 */
				slew-rate = "fast";      /* in zephyr/boards/nxp/frdm_k64f/frdm_k64f-pinctrl.dtsi:24 */
			};
		};

		/* node '/pinctrl/pinmux_enet' defined in zephyr/boards/nxp/frdm_k64f/frdm_k64f-pinctrl.dtsi:28 */
		pinmux_enet: pinmux_enet {
			phandle = < 0x18 >; /* in zephyr/boards/nxp/frdm_k64f/frdm_k64f.dts:276 */

			/* node '/pinctrl/pinmux_enet/group1' defined in zephyr/boards/nxp/frdm_k64f/frdm_k64f-pinctrl.dtsi:29 */
			group1 {
				pinmux = < 0x1400400 >,
				         < 0x3000400 >,
				         < 0x3400400 >,
				         < 0x3800400 >,
				         < 0x3c00400 >,
				         < 0x4000400 >,
				         < 0x4400400 >; /* in zephyr/boards/nxp/frdm_k64f/frdm_k64f-pinctrl.dtsi:30 */
				drive-strength = "low"; /* in zephyr/boards/nxp/frdm_k64f/frdm_k64f-pinctrl.dtsi:37 */
				slew-rate = "fast";     /* in zephyr/boards/nxp/frdm_k64f/frdm_k64f-pinctrl.dtsi:38 */
			};
		};

		/* node '/pinctrl/pinmux_enet_mdio' defined in zephyr/boards/nxp/frdm_k64f/frdm_k64f-pinctrl.dtsi:42 */
		pinmux_enet_mdio: pinmux_enet_mdio {
			phandle = < 0x1c >; /* in zephyr/boards/nxp/frdm_k64f/frdm_k64f.dts:289 */

			/* node '/pinctrl/pinmux_enet_mdio/group0' defined in zephyr/boards/nxp/frdm_k64f/frdm_k64f-pinctrl.dtsi:43 */
			group0 {
				pinmux = < 0x10000400 >; /* in zephyr/boards/nxp/frdm_k64f/frdm_k64f-pinctrl.dtsi:44 */
				drive-strength = "low";  /* in zephyr/boards/nxp/frdm_k64f/frdm_k64f-pinctrl.dtsi:45 */
				drive-open-drain;        /* in zephyr/boards/nxp/frdm_k64f/frdm_k64f-pinctrl.dtsi:46 */
				bias-pull-up;            /* in zephyr/boards/nxp/frdm_k64f/frdm_k64f-pinctrl.dtsi:47 */
				slew-rate = "fast";      /* in zephyr/boards/nxp/frdm_k64f/frdm_k64f-pinctrl.dtsi:48 */
			};

			/* node '/pinctrl/pinmux_enet_mdio/group1' defined in zephyr/boards/nxp/frdm_k64f/frdm_k64f-pinctrl.dtsi:51 */
			group1 {
				pinmux = < 0x10400400 >; /* in zephyr/boards/nxp/frdm_k64f/frdm_k64f-pinctrl.dtsi:52 */
				drive-strength = "low";  /* in zephyr/boards/nxp/frdm_k64f/frdm_k64f-pinctrl.dtsi:53 */
				slew-rate = "fast";      /* in zephyr/boards/nxp/frdm_k64f/frdm_k64f-pinctrl.dtsi:54 */
			};
		};

		/* node '/pinctrl/pinmux_ptp' defined in zephyr/boards/nxp/frdm_k64f/frdm_k64f-pinctrl.dtsi:58 */
		pinmux_ptp: pinmux_ptp {
			phandle = < 0x1d >; /* in zephyr/boards/nxp/frdm_k64f/frdm_k64f.dts:302 */

			/* node '/pinctrl/pinmux_ptp/group0' defined in zephyr/boards/nxp/frdm_k64f/frdm_k64f-pinctrl.dtsi:59 */
			group0 {
				pinmux = < 0x24000400 >,
				         < 0x24400400 >,
				         < 0x24800400 >; /* in zephyr/boards/nxp/frdm_k64f/frdm_k64f-pinctrl.dtsi:60 */
				drive-strength = "low";  /* in zephyr/boards/nxp/frdm_k64f/frdm_k64f-pinctrl.dtsi:63 */
				slew-rate = "fast";      /* in zephyr/boards/nxp/frdm_k64f/frdm_k64f-pinctrl.dtsi:64 */
			};
		};

		/* node '/pinctrl/flexcan0_default' defined in zephyr/boards/nxp/frdm_k64f/frdm_k64f-pinctrl.dtsi:68 */
		flexcan0_default: flexcan0_default {
			phandle = < 0x1e >; /* in zephyr/boards/nxp/frdm_k64f/frdm_k64f.dts:308 */

			/* node '/pinctrl/flexcan0_default/group0' defined in zephyr/boards/nxp/frdm_k64f/frdm_k64f-pinctrl.dtsi:69 */
			group0 {
				pinmux = < 0x14c00200 >; /* in zephyr/boards/nxp/frdm_k64f/frdm_k64f-pinctrl.dtsi:70 */
				drive-strength = "low";  /* in zephyr/boards/nxp/frdm_k64f/frdm_k64f-pinctrl.dtsi:71 */
				bias-pull-up;            /* in zephyr/boards/nxp/frdm_k64f/frdm_k64f-pinctrl.dtsi:72 */
				slew-rate = "fast";      /* in zephyr/boards/nxp/frdm_k64f/frdm_k64f-pinctrl.dtsi:73 */
			};

			/* node '/pinctrl/flexcan0_default/group1' defined in zephyr/boards/nxp/frdm_k64f/frdm_k64f-pinctrl.dtsi:76 */
			group1 {
				pinmux = < 0x14800200 >; /* in zephyr/boards/nxp/frdm_k64f/frdm_k64f-pinctrl.dtsi:77 */
				drive-strength = "low";  /* in zephyr/boards/nxp/frdm_k64f/frdm_k64f-pinctrl.dtsi:78 */
				slew-rate = "fast";      /* in zephyr/boards/nxp/frdm_k64f/frdm_k64f-pinctrl.dtsi:79 */
			};
		};

		/* node '/pinctrl/ftm0_default' defined in zephyr/boards/nxp/frdm_k64f/frdm_k64f-pinctrl.dtsi:83 */
		ftm0_default: ftm0_default {
			phandle = < 0x14 >; /* in zephyr/boards/nxp/frdm_k64f/frdm_k64f.dts:189 */

			/* node '/pinctrl/ftm0_default/group0' defined in zephyr/boards/nxp/frdm_k64f/frdm_k64f-pinctrl.dtsi:84 */
			group0 {
				pinmux = < 0x20400400 >; /* in zephyr/boards/nxp/frdm_k64f/frdm_k64f-pinctrl.dtsi:85 */
				drive-strength = "low";  /* in zephyr/boards/nxp/frdm_k64f/frdm_k64f-pinctrl.dtsi:86 */
				slew-rate = "fast";      /* in zephyr/boards/nxp/frdm_k64f/frdm_k64f-pinctrl.dtsi:87 */
			};
		};

		/* node '/pinctrl/ftm3_default' defined in zephyr/boards/nxp/frdm_k64f/frdm_k64f-pinctrl.dtsi:91 */
		ftm3_default: ftm3_default {
			phandle = < 0x15 >; /* in zephyr/boards/nxp/frdm_k64f/frdm_k64f.dts:198 */

			/* node '/pinctrl/ftm3_default/group0' defined in zephyr/boards/nxp/frdm_k64f/frdm_k64f-pinctrl.dtsi:92 */
			group0 {
				pinmux = < 0x22000300 >,
				         < 0x22400300 >; /* in zephyr/boards/nxp/frdm_k64f/frdm_k64f-pinctrl.dtsi:93 */
				drive-strength = "low";  /* in zephyr/boards/nxp/frdm_k64f/frdm_k64f-pinctrl.dtsi:95 */
				slew-rate = "fast";      /* in zephyr/boards/nxp/frdm_k64f/frdm_k64f-pinctrl.dtsi:96 */
			};
		};

		/* node '/pinctrl/i2c0_default' defined in zephyr/boards/nxp/frdm_k64f/frdm_k64f-pinctrl.dtsi:100 */
		i2c0_default: i2c0_default {
			phandle = < 0x4 >; /* in zephyr/boards/nxp/frdm_k64f/frdm_k64f.dts:147 */

			/* node '/pinctrl/i2c0_default/group0' defined in zephyr/boards/nxp/frdm_k64f/frdm_k64f-pinctrl.dtsi:101 */
			group0 {
				pinmux = < 0x46000500 >,
				         < 0x46400500 >; /* in zephyr/boards/nxp/frdm_k64f/frdm_k64f-pinctrl.dtsi:102 */
				drive-strength = "low";  /* in zephyr/boards/nxp/frdm_k64f/frdm_k64f-pinctrl.dtsi:104 */
				drive-open-drain;        /* in zephyr/boards/nxp/frdm_k64f/frdm_k64f-pinctrl.dtsi:105 */
				slew-rate = "fast";      /* in zephyr/boards/nxp/frdm_k64f/frdm_k64f-pinctrl.dtsi:106 */
			};
		};

		/* node '/pinctrl/ptp_default' defined in zephyr/boards/nxp/frdm_k64f/frdm_k64f-pinctrl.dtsi:111 */
		ptp_default: ptp_default {

			/* node '/pinctrl/ptp_default/group0' defined in zephyr/boards/nxp/frdm_k64f/frdm_k64f-pinctrl.dtsi:112 */
			group0 {
				pinmux = < 0x24000400 >,
				         < 0x24400400 >,
				         < 0x24800400 >; /* in zephyr/boards/nxp/frdm_k64f/frdm_k64f-pinctrl.dtsi:113 */
				drive-strength = "low";  /* in zephyr/boards/nxp/frdm_k64f/frdm_k64f-pinctrl.dtsi:116 */
				slew-rate = "fast";      /* in zephyr/boards/nxp/frdm_k64f/frdm_k64f-pinctrl.dtsi:117 */
			};
		};

		/* node '/pinctrl/spi0_default' defined in zephyr/boards/nxp/frdm_k64f/frdm_k64f-pinctrl.dtsi:122 */
		spi0_default: spi0_default {
			phandle = < 0xf >; /* in zephyr/boards/nxp/frdm_k64f/frdm_k64f.dts:160 */

			/* node '/pinctrl/spi0_default/group0' defined in zephyr/boards/nxp/frdm_k64f/frdm_k64f-pinctrl.dtsi:123 */
			group0 {
				pinmux = < 0x30000200 >,
				         < 0x30400200 >,
				         < 0x30800200 >,
				         < 0x30c00200 >; /* in zephyr/boards/nxp/frdm_k64f/frdm_k64f-pinctrl.dtsi:124 */
				drive-strength = "low";  /* in zephyr/boards/nxp/frdm_k64f/frdm_k64f-pinctrl.dtsi:128 */
				slew-rate = "fast";      /* in zephyr/boards/nxp/frdm_k64f/frdm_k64f-pinctrl.dtsi:129 */
			};
		};

		/* node '/pinctrl/spi1_default' defined in zephyr/boards/nxp/frdm_k64f/frdm_k64f-pinctrl.dtsi:133 */
		spi1_default: spi1_default {
			phandle = < 0x12 >; /* in zephyr/boards/nxp/frdm_k64f/frdm_k64f.dts:166 */

			/* node '/pinctrl/spi1_default/group0' defined in zephyr/boards/nxp/frdm_k64f/frdm_k64f-pinctrl.dtsi:134 */
			group0 {
				pinmux = < 0x41000200 >,
				         < 0x40800200 >,
				         < 0x40c00700 >,
				         < 0x40400700 >; /* in zephyr/boards/nxp/frdm_k64f/frdm_k64f-pinctrl.dtsi:135 */
				drive-strength = "low";  /* in zephyr/boards/nxp/frdm_k64f/frdm_k64f-pinctrl.dtsi:139 */
				slew-rate = "fast";      /* in zephyr/boards/nxp/frdm_k64f/frdm_k64f-pinctrl.dtsi:140 */
			};
		};

		/* node '/pinctrl/uart0_default' defined in zephyr/boards/nxp/frdm_k64f/frdm_k64f-pinctrl.dtsi:144 */
		uart0_default: uart0_default {
			phandle = < 0x6 >; /* in zephyr/boards/nxp/frdm_k64f/frdm_k64f.dts:206 */

			/* node '/pinctrl/uart0_default/group0' defined in zephyr/boards/nxp/frdm_k64f/frdm_k64f-pinctrl.dtsi:145 */
			group0 {
				pinmux = < 0x14000300 >,
				         < 0x14400300 >; /* in zephyr/boards/nxp/frdm_k64f/frdm_k64f-pinctrl.dtsi:146 */
				drive-strength = "low";  /* in zephyr/boards/nxp/frdm_k64f/frdm_k64f-pinctrl.dtsi:148 */
				slew-rate = "fast";      /* in zephyr/boards/nxp/frdm_k64f/frdm_k64f-pinctrl.dtsi:149 */
			};
		};

		/* node '/pinctrl/uart2_default' defined in zephyr/boards/nxp/frdm_k64f/frdm_k64f-pinctrl.dtsi:154 */
		uart2_default: uart2_default {
			phandle = < 0x7 >; /* in zephyr/boards/nxp/frdm_k64f/frdm_k64f.dts:211 */

			/* node '/pinctrl/uart2_default/group0' defined in zephyr/boards/nxp/frdm_k64f/frdm_k64f-pinctrl.dtsi:155 */
			group0 {
				pinmux = < 0x30400300 >,
				         < 0x30000300 >,
				         < 0x30800300 >,
				         < 0x30c00300 >; /* in zephyr/boards/nxp/frdm_k64f/frdm_k64f-pinctrl.dtsi:156 */
				drive-strength = "low";  /* in zephyr/boards/nxp/frdm_k64f/frdm_k64f-pinctrl.dtsi:160 */
				slew-rate = "fast";      /* in zephyr/boards/nxp/frdm_k64f/frdm_k64f-pinctrl.dtsi:161 */
			};
		};

		/* node '/pinctrl/uart3_default' defined in zephyr/boards/nxp/frdm_k64f/frdm_k64f-pinctrl.dtsi:166 */
		uart3_default: uart3_default {
			phandle = < 0x8 >; /* in zephyr/boards/nxp/frdm_k64f/frdm_k64f.dts:116 */

			/* node '/pinctrl/uart3_default/group0' defined in zephyr/boards/nxp/frdm_k64f/frdm_k64f-pinctrl.dtsi:167 */
			group0 {
				pinmux = < 0x24000300 >,
				         < 0x24400300 >; /* in zephyr/boards/nxp/frdm_k64f/frdm_k64f-pinctrl.dtsi:168 */
				drive-strength = "low";  /* in zephyr/boards/nxp/frdm_k64f/frdm_k64f-pinctrl.dtsi:170 */
				slew-rate = "fast";      /* in zephyr/boards/nxp/frdm_k64f/frdm_k64f-pinctrl.dtsi:171 */
			};
		};
	};

	/* node '/leds' defined in zephyr/boards/nxp/frdm_k64f/frdm_k64f.dts:40 */
	leds {
		compatible = "gpio-leds"; /* in zephyr/boards/nxp/frdm_k64f/frdm_k64f.dts:41 */

		/* node '/leds/led_0' defined in zephyr/boards/nxp/frdm_k64f/frdm_k64f.dts:43 */
		red_led: led_0 {
			gpios = < &gpiob 0x16 0x1 >; /* in zephyr/boards/nxp/frdm_k64f/frdm_k64f.dts:44 */
			label = "User LD1";          /* in zephyr/boards/nxp/frdm_k64f/frdm_k64f.dts:45 */
		};

		/* node '/leds/led_1' defined in zephyr/boards/nxp/frdm_k64f/frdm_k64f.dts:48 */
		green_led: led_1 {
			gpios = < &gpioe 0x1a 0x1 >; /* in zephyr/boards/nxp/frdm_k64f/frdm_k64f.dts:49 */
			label = "User LD2";          /* in zephyr/boards/nxp/frdm_k64f/frdm_k64f.dts:50 */
		};

		/* node '/leds/led_2' defined in zephyr/boards/nxp/frdm_k64f/frdm_k64f.dts:53 */
		blue_led: led_2 {
			gpios = < &gpiob 0x15 0x1 >; /* in zephyr/boards/nxp/frdm_k64f/frdm_k64f.dts:54 */
			label = "User LD3";          /* in zephyr/boards/nxp/frdm_k64f/frdm_k64f.dts:55 */
		};
	};

	/* node '/gpio_keys' defined in zephyr/boards/nxp/frdm_k64f/frdm_k64f.dts:59 */
	gpio_keys {
		compatible = "gpio-keys"; /* in zephyr/boards/nxp/frdm_k64f/frdm_k64f.dts:60 */

		/* node '/gpio_keys/button_0' defined in zephyr/boards/nxp/frdm_k64f/frdm_k64f.dts:62 */
		user_button_2: button_0 {
			label = "User SW2";         /* in zephyr/boards/nxp/frdm_k64f/frdm_k64f.dts:63 */
			gpios = < &gpioc 0x6 0x1 >; /* in zephyr/boards/nxp/frdm_k64f/frdm_k64f.dts:64 */
			zephyr,code = < 0xb >;      /* in zephyr/boards/nxp/frdm_k64f/frdm_k64f.dts:65 */
		};

		/* node '/gpio_keys/button_1' defined in zephyr/boards/nxp/frdm_k64f/frdm_k64f.dts:68 */
		user_button_3: button_1 {
			label = "User SW3";         /* in zephyr/boards/nxp/frdm_k64f/frdm_k64f.dts:69 */
			gpios = < &gpioa 0x4 0x1 >; /* in zephyr/boards/nxp/frdm_k64f/frdm_k64f.dts:70 */
			zephyr,code = < 0x2 >;      /* in zephyr/boards/nxp/frdm_k64f/frdm_k64f.dts:71 */
		};
	};

	/* node '/connector' defined in zephyr/boards/nxp/frdm_k64f/frdm_k64f.dts:75 */
	arduino_header: connector {
		compatible = "arduino-header-r3";          /* in zephyr/boards/nxp/frdm_k64f/frdm_k64f.dts:76 */
		#gpio-cells = < 0x2 >;                     /* in zephyr/boards/nxp/frdm_k64f/frdm_k64f.dts:77 */
		gpio-map-mask = < 0xffffffff 0xffffffc0 >; /* in zephyr/boards/nxp/frdm_k64f/frdm_k64f.dts:78 */
		gpio-map-pass-thru = < 0x0 0x3f >;         /* in zephyr/boards/nxp/frdm_k64f/frdm_k64f.dts:79 */
		gpio-map = < 0x0 0x0 &gpiob 0x2 0x0 >,
		           < 0x1 0x0 &gpiob 0x3 0x0 >,
		           < 0x2 0x0 &gpiob 0xa 0x0 >,
		           < 0x3 0x0 &gpiob 0xb 0x0 >,
		           < 0x4 0x0 &gpioc 0xb 0x0 >,
		           < 0x5 0x0 &gpioc 0xa 0x0 >,
		           < 0x6 0x0 &gpioc 0x10 0x0 >,
		           < 0x7 0x0 &gpioc 0x11 0x0 >,
		           < 0x8 0x0 &gpiob 0x9 0x0 >,
		           < 0x9 0x0 &gpioa 0x1 0x0 >,
		           < 0xa 0x0 &gpiob 0x17 0x0 >,
		           < 0xb 0x0 &gpioa 0x2 0x0 >,
		           < 0xc 0x0 &gpioc 0x2 0x0 >,
		           < 0xd 0x0 &gpioc 0x3 0x0 >,
		           < 0xe 0x0 &gpioc 0xc 0x0 >,
		           < 0xf 0x0 &gpioc 0x4 0x0 >,
		           < 0x10 0x0 &gpiod 0x0 0x0 >,
		           < 0x11 0x0 &gpiod 0x2 0x0 >,
		           < 0x12 0x0 &gpiod 0x3 0x0 >,
		           < 0x13 0x0 &gpiod 0x1 0x0 >,
		           < 0x14 0x0 &gpioe 0x19 0x0 >,
		           < 0x15 0x0 &gpioe 0x18 0x0 >;   /* in zephyr/boards/nxp/frdm_k64f/frdm_k64f.dts:80 */
	};

	/* node '/connector_arduino_r3' defined in btr-shields/boards/extend/nxp/frdm_k64f/arduino_r3_socket.dtsi:31 */
	frdm_ard: arduino_r3: connector_arduino_r3 {
		compatible = "socket,arduino-r3";          /* in btr-shields/boards/extend/nxp/frdm_k64f/arduino_r3_socket.dtsi:32 */
		#gpio-cells = < 0x2 >;                     /* in btr-shields/boards/extend/nxp/frdm_k64f/arduino_r3_socket.dtsi:33 */
		gpio-map-mask = < 0xffffffff 0xffffffc0 >; /* in btr-shields/boards/extend/nxp/frdm_k64f/arduino_r3_socket.dtsi:34 */
		gpio-map-pass-thru = < 0x0 0x3f >;         /* in btr-shields/boards/extend/nxp/frdm_k64f/arduino_r3_socket.dtsi:35 */
		gpio-map = < 0x0 0x0 &gpiob 0x2 0x0 >,
		           < 0x1 0x0 &gpiob 0x3 0x0 >,
		           < 0x2 0x0 &gpiob 0xa 0x0 >,
		           < 0x3 0x0 &gpiob 0xb 0x0 >,
		           < 0x4 0x0 &gpioc 0xb 0x0 >,
		           < 0x5 0x0 &gpioc 0xa 0x0 >,
		           < 0x6 0x0 &gpioc 0x10 0x0 >,
		           < 0x7 0x0 &gpioc 0x11 0x0 >,
		           < 0x8 0x0 &gpiob 0x9 0x0 >,
		           < 0x9 0x0 &gpioa 0x1 0x0 >,
		           < 0xa 0x0 &gpiob 0x17 0x0 >,
		           < 0xb 0x0 &gpioa 0x2 0x0 >,
		           < 0xc 0x0 &gpioc 0x2 0x0 >,
		           < 0xd 0x0 &gpioc 0x3 0x0 >,
		           < 0xe 0x0 &gpioc 0xc 0x0 >,
		           < 0xf 0x0 &gpioc 0x4 0x0 >,
		           < 0x10 0x0 &gpiod 0x0 0x0 >,
		           < 0x11 0x0 &gpiod 0x2 0x0 >,
		           < 0x12 0x0 &gpiod 0x3 0x0 >,
		           < 0x13 0x0 &gpiod 0x1 0x0 >,
		           < 0x14 0x0 &gpioe 0x19 0x0 >,
		           < 0x15 0x0 &gpioe 0x18 0x0 >;   /* in btr-shields/boards/extend/nxp/frdm_k64f/arduino_r3_socket.dtsi:36 */
		socket,i2c = < &i2c0 >;                    /* in btr-shields/boards/extend/nxp/frdm_k64f/arduino_r3_socket.dtsi:59 */
		socket,spi = < &spi0 >;                    /* in btr-shields/boards/extend/nxp/frdm_k64f/arduino_r3_socket.dtsi:60 */
		socket,uart = < &uart3 >;                  /* in btr-shields/boards/extend/nxp/frdm_k64f/arduino_r3_socket.dtsi:61 */
		socket,stackable;                          /* in btr-shields/boards/extend/nxp/frdm_k64f/arduino_r3_socket.dtsi:62 */
		#io-channel-cells = < 0x1 >;               /* in btr-shields/boards/extend/nxp/frdm_k64f/arduino_r3_socket.dtsi:101 */
		io-channel-map-mask = < 0xffffffff >;      /* in btr-shields/boards/extend/nxp/frdm_k64f/arduino_r3_socket.dtsi:102 */
		io-channel-map-pass-thru = < 0x0 >;        /* in btr-shields/boards/extend/nxp/frdm_k64f/arduino_r3_socket.dtsi:103 */
		io-channel-map = < 0x0 &adc0 0xc >,
		                 < 0x1 &adc0 0xd >,
		                 < 0x2 &adc1 0xe >,
		                 < 0x3 &adc1 0xf >;        /* in btr-shields/boards/extend/nxp/frdm_k64f/arduino_r3_socket.dtsi:104 */
		phandle = < 0x27 >;                        /* in <RIGC_BUILD>/rig/rig-gen.overlay:11 */
	};

	/* node '/adapter_1_mb1' defined in <RIGC_BUILD>/rig/rig-gen.overlay:7 */
	adapter_1_mb1: adapter_1_mb1 {
		#gpio-cells = < 0x2 >;                     /* in <RIGC_BUILD>/rig/rig-gen.overlay:8 */
		gpio-map-mask = < 0xffffffff 0xffffffc0 >; /* in <RIGC_BUILD>/rig/rig-gen.overlay:9 */
		gpio-map-pass-thru = < 0x0 0x3f >;         /* in <RIGC_BUILD>/rig/rig-gen.overlay:10 */
		gpio-map = < 0x2 0x0 &frdm_ard 0x10 0x0 >,
		           < 0x1 0x0 &frdm_ard 0xc 0x0 >,
		           < 0x7 0x0 &frdm_ard 0x8 0x0 >;  /* in <RIGC_BUILD>/rig/rig-gen.overlay:11 */
		phandle = < 0x10 >;                        /* in <RIGC_BUILD>/rig/rig-gen.overlay:26 */
	};

	/* node '/adapter_1_mb2' defined in <RIGC_BUILD>/rig/rig-gen.overlay:15 */
	adapter_1_mb2: adapter_1_mb2 {
		#gpio-cells = < 0x2 >;                     /* in <RIGC_BUILD>/rig/rig-gen.overlay:16 */
		gpio-map-mask = < 0xffffffff 0xffffffc0 >; /* in <RIGC_BUILD>/rig/rig-gen.overlay:17 */
		gpio-map-pass-thru = < 0x0 0x3f >;         /* in <RIGC_BUILD>/rig/rig-gen.overlay:18 */
		gpio-map = < 0x2 0x0 &frdm_ard 0xf 0x0 >,
		           < 0x1 0x0 &frdm_ard 0xb 0x0 >,
		           < 0x7 0x0 &frdm_ard 0x9 0x0 >;  /* in <RIGC_BUILD>/rig/rig-gen.overlay:19 */
		phandle = < 0x11 >;                        /* in <RIGC_BUILD>/rig/rig-gen.overlay:26 */
	};
};
